VERSION ""

NS_ :

BS_:

BU_: VMCU VGGSECUSystem TECU OBDScanT2 HMIIOM EMS ECUspare2 ECUspare1 DACU CIOM BBM

BO_ 2495638185 VMCU_BB2_54P: 8 VMCU
 SG_ MaintOilQuality : 35|3@1+ (1,0) [0|0] ""  EMS
 SG_ FrontParkBrakeOverrideInd_ISig_4 : 53|2@1+ (1,0) [0|0] ""  HMIIOM
 SG_ ECSLimpHomeNotification_ISig_4 : 16|3@1+ (1,0) [0|0] ""  HMIIOM
 SG_ MirrorHeatUnavailable_Ind : 30|2@1+ (1,0) [0|0] ""  HMIIOM
 SG_ MaintenanceResetStatus : 19|3@1+ (1,0) [0|0] ""  HMIIOM
 SG_ ParkBrakeApplicationMode : 43|3@1+ (1,0) [0|0] ""  VGGSECUSystem,HMIIOM
 SG_ MaintOilReset : 38|2@1+ (1,0) [0|0] ""  EMS
 SG_ RssInhibStartEngine_rqst_ISig_4 : 6|2@1+ (1,0) [0|0] ""  HMIIOM
 SG_ PositionLightRequest_status : 2|2@1+ (1,0) [0|0] ""  BBM,HMIIOM
 SG_ ExtraBBTailLiftStatus_ISig_4 : 4|2@1+ (1,0) [0|0] ""  CIOM
 SG_ MaintenanceNotification_ISig_4 : 32|3@1+ (1,0) [0|0] ""  VGGSECUSystem,HMIIOM
 SG_ ExtraBBSlidable5thWheelStatus : 0|2@1+ (1,0) [0|0] ""  CIOM
 SG_ ParkBrakeReleasePossible_stat : 10|2@1+ (1,0) [0|0] ""  HMIIOM,VGGSECUSystem,TECU
 SG_ LoadDistributionALDChangeACK_ISi : 48|3@1+ (1,0) [0|0] ""  CIOM,HMIIOM
 SG_ PoorAirPressureInfo_UB_ISig_4 : 55|1@1+ (1,0) [0|0] ""  BBM,VGGSECUSystem,HMIIOM
 SG_ ParkBrakeReleaseMode_ISig_4 : 40|3@1+ (1,0) [0|0] ""  HMIIOM
 SG_ ParkBrakeWorkshopMode_ISig_4 : 14|2@1+ (1,0) [0|0] ""  HMIIOM
 SG_ ExtraBBContainerUnlockStatus : 46|2@1+ (1,0) [0|0] ""  CIOM
 SG_ MainBeamRequest_status_ISig_4 : 56|2@1+ (1,0) [0|0] ""  BBM,DACU
 SG_ ExtraBBCraneStatus_ISig_4 : 27|3@1+ (1,0) [0|0] ""  CIOM,BBM
 SG_ AirCompressorStatus : 58|2@1+ (1,0) [0|0] ""  EMS
 SG_ TrailerABSStatus_ISig_4 : 12|2@1+ (1,0) [0|0] ""  TECU,HMIIOM,EMS,DACU
 SG_ RegenInhibitVehicleHeight_ISig_4 : 22|2@1+ (1,0) [0|0] ""  EMS
 SG_ PoorAirPressureInfo_ISig_4 : 51|2@1+ (1,0) [0|0] ""  BBM,HMIIOM,VGGSECUSystem
 SG_ FogLightRearRequest_stat : 8|2@1+ (1,0) [0|0] ""  BBM
 SG_ MainBeam_cmd_ISig_4 : 60|3@1+ (1,0) [0|0] ""  BBM
 SG_ FirstAxleLowerPrioSelected_ISig_ : 24|3@1+ (1,0) [0|0] ""  HMIIOM

BO_ 2482995069 VMCU_BB2_53P: 8 VMCU
 SG_ AuxSwitchBbLoad4_cmd : 14|2@1+ (1,0) [0|0] ""  BBM
 SG_ AuxSwitchBbLoad1_Status_ISig_4 : 0|2@1+ (1,0) [0|0] ""  CIOM,BBM
 SG_ BrakeLightConvoy_rqst_UB_ISig_4 : 45|1@1+ (1,0) [0|0] ""  BBM
 SG_ AccPedalTestPresentationStatus : 51|3@1+ (1,0) [0|0] ""  HMIIOM,VGGSECUSystem
 SG_ AuxSwitchBbLoad3_cmd : 12|2@1+ (1,0) [0|0] ""  BBM
 SG_ BatterySOCTrustLevel_ISig_4 : 56|8@1+ (0.5,0) [0|127.5] "Percent"  HMIIOM
 SG_ AuxSwitchBbLoad4_Status_ISig_4 : 6|2@1+ (1,0) [0|0] ""  CIOM,BBM
 SG_ BrakeLightConvoy_rqst_ISig_4 : 30|2@1+ (1,0) [0|0] ""  BBM
 SG_ DoorWarningLight_cmd_ISig_4 : 38|2@1+ (1,0) [0|0] ""  CIOM
 SG_ BlackOutandConvoyMode_rqst_ISig_ : 35|3@1+ (1,0) [0|0] ""  HMIIOM,DACU,BBM
 SG_ DirIndicatorRqstLights_stat : 32|3@1+ (1,0) [0|0] ""  DACU,BBM
 SG_ DoubleFrontAxleSteeringWarning_I : 20|2@1+ (1,0) [0|0] ""  HMIIOM
 SG_ ASLActive : 22|2@1+ (1,0) [0|0] ""  HMIIOM
 SG_ DippedBeamRequest_status : 24|2@1+ (1,0) [0|0] ""  BBM
 SG_ AuxSwitchBbLoad3_Status_ISig_4 : 4|2@1+ (1,0) [0|0] ""  CIOM,BBM
 SG_ DoorInstepLight_cmd_ISig_4 : 43|2@1+ (1,0) [0|0] ""  CIOM
 SG_ DRLRequest_status : 26|2@1+ (1,0) [0|0] ""  BBM
 SG_ AuxSwitchBbLoad6_Status_ISig_4 : 10|2@1+ (1,0) [0|0] ""  BBM,CIOM
 SG_ AuxSwitchBbLoad2_Status_ISig_4 : 2|2@1+ (1,0) [0|0] ""  CIOM,BBM
 SG_ AuxSwitchBbLoad5_cmd : 16|2@1+ (1,0) [0|0] ""  BBM
 SG_ PBReleaseInhibit_EPBState_ISig_4 : 48|3@1+ (1,0) [0|0] ""  BBM
 SG_ ExtStaticTrailerBrake_Stat_ISig_ : 46|2@1+ (1,0) [0|0] ""  HMIIOM,BBM
 SG_ AuxSwitchBbLoad5_Status_ISig_4 : 8|2@1+ (1,0) [0|0] ""  CIOM,BBM
 SG_ AuxSwitchBbLoad6_cmd : 18|2@1+ (1,0) [0|0] ""  BBM

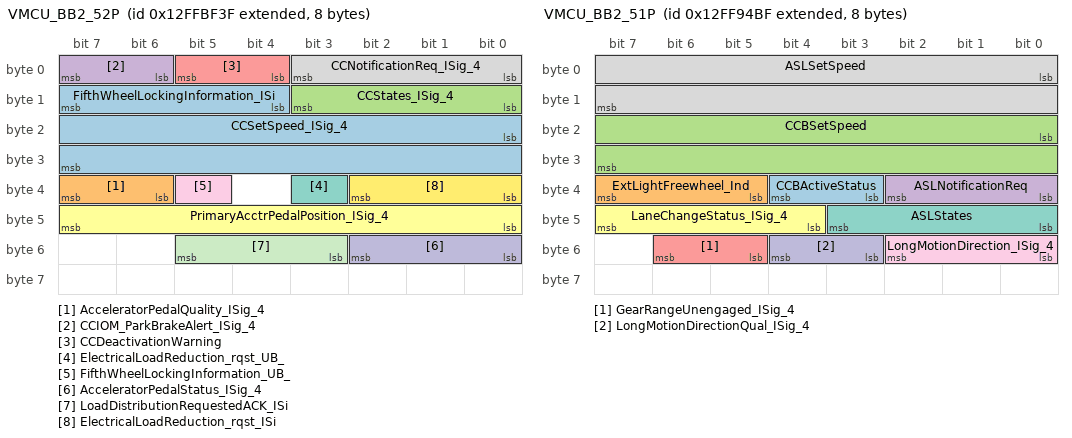
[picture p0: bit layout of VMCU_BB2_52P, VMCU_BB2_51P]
BO_ 2466234175 VMCU_BB2_52P: 8 VMCU
 SG_ CCSetSpeed_ISig_4 : 16|16@1+ (0.00390625,0) [0|255.99609375] "Km_per_h"  TECU,BBM,DACU,HMIIOM
 SG_ AcceleratorPedalQuality_ISig_4 : 38|2@1+ (1,0) [0|0] ""  BBM
 SG_ CCStates_ISig_4 : 8|4@1+ (1,0) [0|0] ""  CIOM,DACU,HMIIOM,BBM
 SG_ CCIOM_ParkBrakeAlert_ISig_4 : 6|2@1+ (1,0) [0|0] ""  HMIIOM
 SG_ CCDeactivationWarning : 4|2@1+ (1,0) [0|0] ""  DACU
 SG_ PrimaryAcctrPedalPosition_ISig_4 : 40|8@1+ (0.4,0) [0|102] "Percent"  BBM
 SG_ ElectricalLoadReduction_rqst_UB_ : 35|1@1+ (1,0) [0|0] ""  CIOM
 SG_ CCNotificationReq_ISig_4 : 0|4@1+ (1,0) [0|0] ""  HMIIOM
 SG_ FifthWheelLockingInformation_UB_ : 37|1@1+ (1,0) [0|0] ""  BBM,HMIIOM
 SG_ AcceleratorPedalStatus_ISig_4 : 48|3@1+ (1,0) [0|0] ""  CIOM,BBM
 SG_ LoadDistributionRequestedACK_ISi : 51|3@1+ (1,0) [0|0] ""  CIOM
 SG_ ElectricalLoadReduction_rqst_ISi : 32|3@1+ (1,0) [0|0] ""  CIOM
 SG_ FifthWheelLockingInformation_ISi : 12|4@1+ (1,0) [0|0] ""  HMIIOM

BO_ 2466223295 VMCU_BB2_51P: 8 VMCU
 SG_ CCBActiveStatus : 35|2@1+ (1,0) [0|0] ""  HMIIOM
 SG_ ExtLightFreewheel_Ind : 37|3@1+ (1,0) [0|0] ""  HMIIOM
 SG_ CCBSetSpeed : 16|16@1+ (0.00390625,0) [0|255.99609375] "Km_per_h"  DACU,TECU,HMIIOM
 SG_ ASLNotificationReq : 32|3@1+ (1,0) [0|0] ""  HMIIOM
 SG_ GearRangeUnengaged_ISig_4 : 53|2@1+ (1,0) [0|0] ""  HMIIOM
 SG_ LaneChangeStatus_ISig_4 : 44|4@1+ (1,0) [0|0] ""  DACU
 SG_ ASLStates : 40|4@1+ (1,0) [0|0] ""  CIOM,HMIIOM
 SG_ ASLSetSpeed : 0|16@1+ (0.00390625,0) [0|255.99609375] "Km_per_h"  HMIIOM
 SG_ LongMotionDirection_ISig_4 : 48|3@1+ (1,0) [0|0] ""  BBM,CIOM
 SG_ LongMotionDirectionQual_ISig_4 : 51|2@1+ (1,0) [0|0] ""  CIOM

BO_ 2499796773 VMCU_BB2_34S_FCM: 8 CIOM
 SG_ VMCU_BB2_34S_FCS : 0|64@1+ (1,0) [0|0] ""  VMCU

BO_ 2499796772 VMCU_BB2_34S: 16 VMCU
 SG_ KeyID_KeyAuthEncrypted : 0|128@1+ (1,0) [0|0] ""  CIOM

BO_ 2566560037 VMCU_BB2_33S_FCM: 8 HMIIOM
 SG_ VMCU_BB2_33S_FCS : 0|64@1+ (1,0) [0|0] ""  VMCU

CM_ SG_ 2466234175 CCSetSpeed_ISig_4 "65024 - 65279 Error ; 65280 - 65535 Not available";
CM_ SG_ 2466223295 CCBSetSpeed "65024 - 65279 Error ; 65280 - 65535 Not available";
CM_ SG_ 2466223295 ASLSetSpeed "65024 - 65279 Error ; 65280 - 65535 Not available";
BA_DEF_ BO_  "GenMsgStartDelayTime" INT 0 0;
BA_DEF_ BO_  "GenMsgDelayTime" INT 0 0;
BA_DEF_ BO_  "GenMsgCycleTime" INT 0 0;
BA_DEF_ BO_  "GenMsgSendType" ENUM  "Cyclic","NotUsed","NotUsed","NotUsed","NotUsed","NotUsed","NotUsed","IfActive","NoMsgSendType","NotUsed";
BA_DEF_ SG_  "GenSigStartValue" INT 0 0;
BA_DEF_ SG_  "GenSigCycleTimeActive" INT 0 0;
BA_DEF_ SG_  "GenSigCycleTime" INT 0 0;
BA_DEF_ SG_  "GenSigSendType" ENUM  "Cyclic","OnWrite","OnWriteWithRepetition","OnChange","OnChangeWithRepetition","IfActive","IfActiveWithRepetition","NoSigSendType","NotUsed","NotUsed","NotUsed","NotUsed","NotUsed";
BA_DEF_ BO_  "VFrameFormat" ENUM  "StandardCAN","ExtendedCAN","reserved","J1939PG";
BA_DEF_ SG_  "SigType" ENUM  "Default","Range","RangeSigned","ASCII","Discrete","Control","ReferencePGN","DTC","StringDelimiter","StringLength","StringLengthControl";
BA_DEF_ SG_  "SeToolVersion_SIGNAL" STRING ;
BA_DEF_ SG_  "SeToolUniqueID_SIGNAL" STRING ;
BA_DEF_ SG_  "SeToolOwnerSigGroup_SIGNAL" STRING ;
BA_DEF_ SG_  "SeToolOwnerSigGroupID_SIGNAL" STRING ;
BA_DEF_ SG_  "SeToolName_SIGNAL" STRING ;
BA_DEF_ SG_  "SeToolItemID_SIGNAL" STRING ;
BA_DEF_ SG_  "SeToolAncestorID_SIGNAL" STRING ;
BA_DEF_ SG_  "Platform_VMCU1_Sig" ENUM  "No","Yes";
BA_DEF_ BO_  "NmAsrMessage" ENUM  "No","Yes";
BA_DEF_ SG_  "NeedsUpdateBit" ENUM  "No","Yes";
BA_DEF_ SG_  "MmAnSignal" ENUM  "No","Yes";
BA_DEF_ SG_  "GenSigMaxLatency" INT 0 65535;
BA_DEF_ SG_  "GenSigILSupport" ENUM  "Yes","No";
BA_DEF_ BO_  "GenMsgRequestable" INT 0 1;
BA_DEF_ BO_  "GenMsgILSupport" ENUM  "No","Yes";
BA_DEF_ BO_  "DiagUUDTResponse" ENUM  "No","Yes";
BA_DEF_ BO_  "DiagState" ENUM  "No","Yes";
BA_DEF_ BO_  "DiagResponse" ENUM  "No","Yes";
BA_DEF_ BO_  "DiagRequest" ENUM  "No","Yes";
BA_DEF_ BO_  "DiagConnection" HEX 0 65535;
BA_DEF_ BO_  "CanTpSTmin" INT 0 255;
BA_DEF_ BO_  "CanTpFcFrameId" HEX 0 2147483647;
BA_DEF_ BO_  "CanTpBs" INT 0 255;
BA_DEF_ SG_  "SystemSignalLongSymbol" STRING ;
BA_DEF_REL_ BU_SG_REL_  "GenSigTimeoutTime" INT 0 65535;
BA_DEF_REL_ BU_SG_REL_  "GenSigFirstTimeoutTime" INT 0 65535;
BA_DEF_DEF_  "GenMsgStartDelayTime" 0;
BA_DEF_DEF_  "GenMsgDelayTime" 0;
BA_DEF_DEF_  "GenMsgCycleTime" 0;
BA_DEF_DEF_  "GenMsgSendType" "Cyclic";
BA_DEF_DEF_  "GenSigStartValue" 0;
BA_DEF_DEF_  "GenSigCycleTimeActive" 0;
BA_DEF_DEF_  "GenSigCycleTime" 0;
BA_DEF_DEF_  "GenSigSendType" "Cyclic";
BA_DEF_DEF_  "VFrameFormat" "ExtendedCAN";
BA_DEF_DEF_  "SigType" "Default";
BA_DEF_DEF_  "SeToolVersion_SIGNAL" "";
BA_DEF_DEF_  "SeToolUniqueID_SIGNAL" "";
BA_DEF_DEF_  "SeToolOwnerSigGroup_SIGNAL" "";
BA_DEF_DEF_  "SeToolOwnerSigGroupID_SIGNAL" "";
BA_DEF_DEF_  "SeToolName_SIGNAL" "";
BA_DEF_DEF_  "SeToolItemID_SIGNAL" "";
BA_DEF_DEF_  "SeToolAncestorID_SIGNAL" "";
BA_DEF_DEF_  "Platform_VMCU1_Sig" "No";
BA_DEF_DEF_  "NmAsrMessage" "No";
BA_DEF_DEF_  "NeedsUpdateBit" "No";
BA_DEF_DEF_  "MmAnSignal" "No";
BA_DEF_DEF_  "GenSigMaxLatency" 0;
BA_DEF_DEF_  "GenSigILSupport" "Yes";
BA_DEF_DEF_  "GenMsgRequestable" 1;
BA_DEF_DEF_  "GenMsgILSupport" "Yes";
BA_DEF_DEF_  "DiagUUDTResponse" "No";
BA_DEF_DEF_  "DiagState" "No";
BA_DEF_DEF_  "DiagResponse" "No";
BA_DEF_DEF_  "DiagRequest" "No";
BA_DEF_DEF_  "DiagConnection" 0;
BA_DEF_DEF_  "CanTpSTmin" 0;
BA_DEF_DEF_  "CanTpFcFrameId" 2147483647;
BA_DEF_DEF_  "CanTpBs" 255;
BA_DEF_DEF_REL_ "GenSigTimeoutTime" 0;
BA_DEF_DEF_REL_ "GenSigFirstTimeoutTime" 0;
BA_DEF_DEF_  "SystemSignalLongSymbol" "";
BA_ "GenMsgCycleTime" BO_ 2495638185 75;
BA_ "GenMsgStartDelayTime" BO_ 2495638185 10;
BA_ "GenMsgCycleTime" BO_ 2482995069 50;
BA_ "GenMsgStartDelayTime" BO_ 2482995069 15;
BA_ "GenMsgCycleTime" BO_ 2466234175 35;
BA_ "GenMsgCycleTime" BO_ 2466223295 30;
BA_ "GenMsgStartDelayTime" BO_ 2466223295 15;
BA_ "GenMsgILSupport" BO_ 2499796773 0;
BA_ "GenMsgSendType" BO_ 2499796773 8;
BA_ "CanTpFcFrameId" BO_ 2499796772 352313125;
BA_ "GenMsgSendType" BO_ 2499796772 8;
BA_ "GenMsgDelayTime" BO_ 2499796772 80;
BA_ "GenMsgILSupport" BO_ 2566560037 0;
BA_ "GenMsgSendType" BO_ 2566560037 8;
BA_ "GenSigCycleTime" SG_ 2495638185 MaintOilQuality 100;
BA_ "GenSigCycleTimeActive" SG_ 2495638185 MaintOilQuality 100;
BA_ "GenSigStartValue" SG_ 2495638185 MaintOilQuality 7;
BA_ "GenSigMaxLatency" SG_ 2495638185 MaintOilQuality 112;
BA_ "Platform_VMCU1_Sig" SG_ 2495638185 MaintOilQuality 1;
BA_ "GenSigCycleTime" SG_ 2495638185 FrontParkBrakeOverrideInd_ISig_4 100;
BA_ "GenSigCycleTimeActive" SG_ 2495638185 FrontParkBrakeOverrideInd_ISig_4 100;
BA_ "GenSigStartValue" SG_ 2495638185 FrontParkBrakeOverrideInd_ISig_4 3;
BA_ "Platform_VMCU1_Sig" SG_ 2495638185 FrontParkBrakeOverrideInd_ISig_4 1;
BA_ "GenSigCycleTime" SG_ 2495638185 ECSLimpHomeNotification_ISig_4 100;
BA_ "GenSigCycleTimeActive" SG_ 2495638185 ECSLimpHomeNotification_ISig_4 100;
BA_ "GenSigStartValue" SG_ 2495638185 ECSLimpHomeNotification_ISig_4 7;
BA_ "GenSigMaxLatency" SG_ 2495638185 ECSLimpHomeNotification_ISig_4 63;
BA_ "Platform_VMCU1_Sig" SG_ 2495638185 ECSLimpHomeNotification_ISig_4 1;
BA_ "GenSigCycleTime" SG_ 2495638185 MirrorHeatUnavailable_Ind 100;
BA_ "GenSigCycleTimeActive" SG_ 2495638185 MirrorHeatUnavailable_Ind 100;
BA_ "GenSigStartValue" SG_ 2495638185 MirrorHeatUnavailable_Ind 3;
BA_ "Platform_VMCU1_Sig" SG_ 2495638185 MirrorHeatUnavailable_Ind 1;
BA_ "GenSigCycleTime" SG_ 2495638185 MaintenanceResetStatus 100;
BA_ "GenSigCycleTimeActive" SG_ 2495638185 MaintenanceResetStatus 100;
BA_ "GenSigStartValue" SG_ 2495638185 MaintenanceResetStatus 7;
BA_ "Platform_VMCU1_Sig" SG_ 2495638185 MaintenanceResetStatus 1;
BA_ "GenSigCycleTime" SG_ 2495638185 ParkBrakeApplicationMode 100;
BA_ "GenSigCycleTimeActive" SG_ 2495638185 ParkBrakeApplicationMode 100;
BA_ "GenSigStartValue" SG_ 2495638185 ParkBrakeApplicationMode 7;
BA_ "GenSigMaxLatency" SG_ 2495638185 ParkBrakeApplicationMode 112;
BA_ "Platform_VMCU1_Sig" SG_ 2495638185 ParkBrakeApplicationMode 1;
BA_ "GenSigCycleTime" SG_ 2495638185 MaintOilReset 100;
BA_ "GenSigCycleTimeActive" SG_ 2495638185 MaintOilReset 100;
BA_ "GenSigStartValue" SG_ 2495638185 MaintOilReset 3;
BA_ "GenSigMaxLatency" SG_ 2495638185 MaintOilReset 112;
BA_ "Platform_VMCU1_Sig" SG_ 2495638185 MaintOilReset 1;
BA_ "GenSigCycleTime" SG_ 2495638185 RssInhibStartEngine_rqst_ISig_4 100;
BA_ "GenSigCycleTimeActive" SG_ 2495638185 RssInhibStartEngine_rqst_ISig_4 100;
BA_ "GenSigStartValue" SG_ 2495638185 RssInhibStartEngine_rqst_ISig_4 3;
BA_ "GenSigMaxLatency" SG_ 2495638185 RssInhibStartEngine_rqst_ISig_4 112;
BA_ "Platform_VMCU1_Sig" SG_ 2495638185 RssInhibStartEngine_rqst_ISig_4 1;
BA_ "GenSigCycleTime" SG_ 2495638185 PositionLightRequest_status 100;
BA_ "GenSigCycleTimeActive" SG_ 2495638185 PositionLightRequest_status 100;
BA_ "GenSigStartValue" SG_ 2495638185 PositionLightRequest_status 3;
BA_ "GenSigMaxLatency" SG_ 2495638185 PositionLightRequest_status 112;
BA_ "Platform_VMCU1_Sig" SG_ 2495638185 PositionLightRequest_status 1;
BA_ "GenSigCycleTime" SG_ 2495638185 ExtraBBTailLiftStatus_ISig_4 100;
BA_ "GenSigCycleTimeActive" SG_ 2495638185 ExtraBBTailLiftStatus_ISig_4 100;
BA_ "GenSigStartValue" SG_ 2495638185 ExtraBBTailLiftStatus_ISig_4 3;
BA_ "GenSigMaxLatency" SG_ 2495638185 ExtraBBTailLiftStatus_ISig_4 112;
BA_ "Platform_VMCU1_Sig" SG_ 2495638185 ExtraBBTailLiftStatus_ISig_4 1;
BA_ "GenSigCycleTime" SG_ 2495638185 MaintenanceNotification_ISig_4 100;
BA_ "GenSigCycleTimeActive" SG_ 2495638185 MaintenanceNotification_ISig_4 100;
BA_ "GenSigStartValue" SG_ 2495638185 MaintenanceNotification_ISig_4 7;
BA_ "GenSigMaxLatency" SG_ 2495638185 MaintenanceNotification_ISig_4 112;
BA_ "Platform_VMCU1_Sig" SG_ 2495638185 MaintenanceNotification_ISig_4 1;
BA_ "GenSigCycleTime" SG_ 2495638185 ExtraBBSlidable5thWheelStatus 100;
BA_ "GenSigCycleTimeActive" SG_ 2495638185 ExtraBBSlidable5thWheelStatus 100;
BA_ "GenSigStartValue" SG_ 2495638185 ExtraBBSlidable5thWheelStatus 3;
BA_ "GenSigMaxLatency" SG_ 2495638185 ExtraBBSlidable5thWheelStatus 112;
BA_ "Platform_VMCU1_Sig" SG_ 2495638185 ExtraBBSlidable5thWheelStatus 1;
BA_ "GenSigCycleTime" SG_ 2495638185 ParkBrakeReleasePossible_stat 100;
BA_ "GenSigCycleTimeActive" SG_ 2495638185 ParkBrakeReleasePossible_stat 100;
BA_ "GenSigStartValue" SG_ 2495638185 ParkBrakeReleasePossible_stat 3;
BA_ "GenSigMaxLatency" SG_ 2495638185 ParkBrakeReleasePossible_stat 112;
BA_ "Platform_VMCU1_Sig" SG_ 2495638185 ParkBrakeReleasePossible_stat 1;
BA_ "GenSigCycleTime" SG_ 2495638185 LoadDistributionALDChangeACK_ISi 100;
BA_ "GenSigCycleTimeActive" SG_ 2495638185 LoadDistributionALDChangeACK_ISi 100;
BA_ "GenSigStartValue" SG_ 2495638185 LoadDistributionALDChangeACK_ISi 7;
BA_ "GenSigMaxLatency" SG_ 2495638185 LoadDistributionALDChangeACK_ISi 112;
BA_ "Platform_VMCU1_Sig" SG_ 2495638185 LoadDistributionALDChangeACK_ISi 1;
BA_ "SystemSignalLongSymbol" SG_ 2495638185 LoadDistributionALDChangeACK_ISi "LoadDistributionALDChangeACK_ISig_4";
BA_ "GenSigSendType" SG_ 2495638185 PoorAirPressureInfo_UB_ISig_4 7;
BA_ "Platform_VMCU1_Sig" SG_ 2495638185 PoorAirPressureInfo_UB_ISig_4 1;
BA_ "GenSigCycleTime" SG_ 2495638185 ParkBrakeReleaseMode_ISig_4 100;
BA_ "GenSigCycleTimeActive" SG_ 2495638185 ParkBrakeReleaseMode_ISig_4 100;
BA_ "GenSigStartValue" SG_ 2495638185 ParkBrakeReleaseMode_ISig_4 7;
BA_ "GenSigMaxLatency" SG_ 2495638185 ParkBrakeReleaseMode_ISig_4 112;
BA_ "Platform_VMCU1_Sig" SG_ 2495638185 ParkBrakeReleaseMode_ISig_4 1;
BA_ "GenSigCycleTime" SG_ 2495638185 ParkBrakeWorkshopMode_ISig_4 100;
BA_ "GenSigCycleTimeActive" SG_ 2495638185 ParkBrakeWorkshopMode_ISig_4 100;
BA_ "GenSigStartValue" SG_ 2495638185 ParkBrakeWorkshopMode_ISig_4 3;
BA_ "GenSigMaxLatency" SG_ 2495638185 ParkBrakeWorkshopMode_ISig_4 112;
BA_ "Platform_VMCU1_Sig" SG_ 2495638185 ParkBrakeWorkshopMode_ISig_4 1;
BA_ "GenSigCycleTime" SG_ 2495638185 ExtraBBContainerUnlockStatus 100;
BA_ "GenSigCycleTimeActive" SG_ 2495638185 ExtraBBContainerUnlockStatus 100;
BA_ "GenSigStartValue" SG_ 2495638185 ExtraBBContainerUnlockStatus 3;
BA_ "GenSigMaxLatency" SG_ 2495638185 ExtraBBContainerUnlockStatus 112;
BA_ "Platform_VMCU1_Sig" SG_ 2495638185 ExtraBBContainerUnlockStatus 1;
BA_ "GenSigCycleTime" SG_ 2495638185 MainBeamRequest_status_ISig_4 100;
BA_ "GenSigCycleTimeActive" SG_ 2495638185 MainBeamRequest_status_ISig_4 100;
BA_ "GenSigStartValue" SG_ 2495638185 MainBeamRequest_status_ISig_4 3;
BA_ "GenSigMaxLatency" SG_ 2495638185 MainBeamRequest_status_ISig_4 112;
BA_ "Platform_VMCU1_Sig" SG_ 2495638185 MainBeamRequest_status_ISig_4 1;
BA_ "GenSigCycleTime" SG_ 2495638185 ExtraBBCraneStatus_ISig_4 100;
BA_ "GenSigCycleTimeActive" SG_ 2495638185 ExtraBBCraneStatus_ISig_4 100;
BA_ "GenSigStartValue" SG_ 2495638185 ExtraBBCraneStatus_ISig_4 7;
BA_ "GenSigMaxLatency" SG_ 2495638185 ExtraBBCraneStatus_ISig_4 112;
BA_ "Platform_VMCU1_Sig" SG_ 2495638185 ExtraBBCraneStatus_ISig_4 1;
BA_ "GenSigCycleTime" SG_ 2495638185 AirCompressorStatus 100;
BA_ "GenSigCycleTimeActive" SG_ 2495638185 AirCompressorStatus 100;
BA_ "GenSigStartValue" SG_ 2495638185 AirCompressorStatus 3;
BA_ "Platform_VMCU1_Sig" SG_ 2495638185 AirCompressorStatus 1;
BA_ "GenSigCycleTime" SG_ 2495638185 TrailerABSStatus_ISig_4 100;
BA_ "GenSigCycleTimeActive" SG_ 2495638185 TrailerABSStatus_ISig_4 100;
BA_ "GenSigStartValue" SG_ 2495638185 TrailerABSStatus_ISig_4 3;
BA_ "GenSigMaxLatency" SG_ 2495638185 TrailerABSStatus_ISig_4 112;
BA_ "Platform_VMCU1_Sig" SG_ 2495638185 TrailerABSStatus_ISig_4 1;
BA_ "GenSigCycleTime" SG_ 2495638185 RegenInhibitVehicleHeight_ISig_4 100;
BA_ "GenSigCycleTimeActive" SG_ 2495638185 RegenInhibitVehicleHeight_ISig_4 100;
BA_ "GenSigStartValue" SG_ 2495638185 RegenInhibitVehicleHeight_ISig_4 3;
BA_ "Platform_VMCU1_Sig" SG_ 2495638185 RegenInhibitVehicleHeight_ISig_4 1;
BA_ "GenSigCycleTime" SG_ 2495638185 PoorAirPressureInfo_ISig_4 100;
BA_ "GenSigCycleTimeActive" SG_ 2495638185 PoorAirPressureInfo_ISig_4 100;
BA_ "GenSigStartValue" SG_ 2495638185 PoorAirPressureInfo_ISig_4 3;
BA_ "GenSigMaxLatency" SG_ 2495638185 PoorAirPressureInfo_ISig_4 112;
BA_ "NeedsUpdateBit" SG_ 2495638185 PoorAirPressureInfo_ISig_4 1;
BA_ "Platform_VMCU1_Sig" SG_ 2495638185 PoorAirPressureInfo_ISig_4 1;
BA_ "GenSigCycleTime" SG_ 2495638185 FogLightRearRequest_stat 100;
BA_ "GenSigCycleTimeActive" SG_ 2495638185 FogLightRearRequest_stat 100;
BA_ "GenSigStartValue" SG_ 2495638185 FogLightRearRequest_stat 3;
BA_ "GenSigMaxLatency" SG_ 2495638185 FogLightRearRequest_stat 112;
BA_ "Platform_VMCU1_Sig" SG_ 2495638185 FogLightRearRequest_stat 1;
BA_ "GenSigCycleTime" SG_ 2495638185 MainBeam_cmd_ISig_4 100;
BA_ "GenSigCycleTimeActive" SG_ 2495638185 MainBeam_cmd_ISig_4 100;
BA_ "GenSigStartValue" SG_ 2495638185 MainBeam_cmd_ISig_4 7;
BA_ "Platform_VMCU1_Sig" SG_ 2495638185 MainBeam_cmd_ISig_4 1;
BA_ "SeToolAncestorID_SIGNAL" SG_ 2495638185 MainBeam_cmd_ISig_4 "x0000001D04134EB4";
BA_ "SeToolItemID_SIGNAL" SG_ 2495638185 MainBeam_cmd_ISig_4 "x0000001D04383E5C";
BA_ "SeToolName_SIGNAL" SG_ 2495638185 MainBeam_cmd_ISig_4 "MainBeam_cmd";
BA_ "SeToolVersion_SIGNAL" SG_ 2495638185 MainBeam_cmd_ISig_4 "4";
BA_ "GenSigCycleTime" SG_ 2495638185 FirstAxleLowerPrioSelected_ISig_ 100;
BA_ "GenSigCycleTimeActive" SG_ 2495638185 FirstAxleLowerPrioSelected_ISig_ 100;
BA_ "GenSigStartValue" SG_ 2495638185 FirstAxleLowerPrioSelected_ISig_ 7;
BA_ "GenSigMaxLatency" SG_ 2495638185 FirstAxleLowerPrioSelected_ISig_ 112;
BA_ "Platform_VMCU1_Sig" SG_ 2495638185 FirstAxleLowerPrioSelected_ISig_ 1;
BA_ "SystemSignalLongSymbol" SG_ 2495638185 FirstAxleLowerPrioSelected_ISig_ "FirstAxleLowerPrioSelected_ISig_4";
BA_ "GenSigCycleTime" SG_ 2482995069 AuxSwitchBbLoad4_cmd 100;
BA_ "GenSigCycleTimeActive" SG_ 2482995069 AuxSwitchBbLoad4_cmd 100;
BA_ "GenSigStartValue" SG_ 2482995069 AuxSwitchBbLoad4_cmd 3;
BA_ "GenSigMaxLatency" SG_ 2482995069 AuxSwitchBbLoad4_cmd 63;
BA_ "Platform_VMCU1_Sig" SG_ 2482995069 AuxSwitchBbLoad4_cmd 1;
BA_ "GenSigCycleTime" SG_ 2482995069 AuxSwitchBbLoad1_Status_ISig_4 100;
BA_ "GenSigCycleTimeActive" SG_ 2482995069 AuxSwitchBbLoad1_Status_ISig_4 100;
BA_ "GenSigStartValue" SG_ 2482995069 AuxSwitchBbLoad1_Status_ISig_4 3;
BA_ "GenSigMaxLatency" SG_ 2482995069 AuxSwitchBbLoad1_Status_ISig_4 63;
BA_ "Platform_VMCU1_Sig" SG_ 2482995069 AuxSwitchBbLoad1_Status_ISig_4 1;
BA_ "GenSigSendType" SG_ 2482995069 BrakeLightConvoy_rqst_UB_ISig_4 7;
BA_ "Platform_VMCU1_Sig" SG_ 2482995069 BrakeLightConvoy_rqst_UB_ISig_4 1;
BA_ "GenSigCycleTime" SG_ 2482995069 AccPedalTestPresentationStatus 100;
BA_ "GenSigCycleTimeActive" SG_ 2482995069 AccPedalTestPresentationStatus 100;
BA_ "GenSigStartValue" SG_ 2482995069 AccPedalTestPresentationStatus 7;
BA_ "Platform_VMCU1_Sig" SG_ 2482995069 AccPedalTestPresentationStatus 1;
BA_ "GenSigCycleTime" SG_ 2482995069 AuxSwitchBbLoad3_cmd 100;
BA_ "GenSigCycleTimeActive" SG_ 2482995069 AuxSwitchBbLoad3_cmd 100;
BA_ "GenSigStartValue" SG_ 2482995069 AuxSwitchBbLoad3_cmd 3;
BA_ "GenSigMaxLatency" SG_ 2482995069 AuxSwitchBbLoad3_cmd 63;
BA_ "Platform_VMCU1_Sig" SG_ 2482995069 AuxSwitchBbLoad3_cmd 1;
BA_ "GenSigCycleTime" SG_ 2482995069 BatterySOCTrustLevel_ISig_4 100;
BA_ "GenSigCycleTimeActive" SG_ 2482995069 BatterySOCTrustLevel_ISig_4 100;
BA_ "GenSigStartValue" SG_ 2482995069 BatterySOCTrustLevel_ISig_4 255;
BA_ "Platform_VMCU1_Sig" SG_ 2482995069 BatterySOCTrustLevel_ISig_4 1;
BA_ "GenSigCycleTime" SG_ 2482995069 AuxSwitchBbLoad4_Status_ISig_4 100;
BA_ "GenSigCycleTimeActive" SG_ 2482995069 AuxSwitchBbLoad4_Status_ISig_4 100;
BA_ "GenSigStartValue" SG_ 2482995069 AuxSwitchBbLoad4_Status_ISig_4 3;
BA_ "GenSigMaxLatency" SG_ 2482995069 AuxSwitchBbLoad4_Status_ISig_4 63;
BA_ "Platform_VMCU1_Sig" SG_ 2482995069 AuxSwitchBbLoad4_Status_ISig_4 1;
BA_ "GenSigCycleTime" SG_ 2482995069 BrakeLightConvoy_rqst_ISig_4 100;
BA_ "GenSigCycleTimeActive" SG_ 2482995069 BrakeLightConvoy_rqst_ISig_4 100;
BA_ "GenSigStartValue" SG_ 2482995069 BrakeLightConvoy_rqst_ISig_4 3;
BA_ "NeedsUpdateBit" SG_ 2482995069 BrakeLightConvoy_rqst_ISig_4 1;
BA_ "Platform_VMCU1_Sig" SG_ 2482995069 BrakeLightConvoy_rqst_ISig_4 1;
BA_ "GenSigCycleTime" SG_ 2482995069 DoorWarningLight_cmd_ISig_4 100;
BA_ "GenSigCycleTimeActive" SG_ 2482995069 DoorWarningLight_cmd_ISig_4 100;
BA_ "GenSigStartValue" SG_ 2482995069 DoorWarningLight_cmd_ISig_4 3;
BA_ "Platform_VMCU1_Sig" SG_ 2482995069 DoorWarningLight_cmd_ISig_4 1;
BA_ "GenSigCycleTime" SG_ 2482995069 BlackOutandConvoyMode_rqst_ISig_ 100;
BA_ "GenSigCycleTimeActive" SG_ 2482995069 BlackOutandConvoyMode_rqst_ISig_ 100;
BA_ "GenSigStartValue" SG_ 2482995069 BlackOutandConvoyMode_rqst_ISig_ 7;
BA_ "Platform_VMCU1_Sig" SG_ 2482995069 BlackOutandConvoyMode_rqst_ISig_ 1;
BA_ "SystemSignalLongSymbol" SG_ 2482995069 BlackOutandConvoyMode_rqst_ISig_ "BlackOutandConvoyMode_rqst_ISig_4";
BA_ "GenSigCycleTime" SG_ 2482995069 DirIndicatorRqstLights_stat 100;
BA_ "GenSigCycleTimeActive" SG_ 2482995069 DirIndicatorRqstLights_stat 100;
BA_ "GenSigStartValue" SG_ 2482995069 DirIndicatorRqstLights_stat 7;
BA_ "GenSigMaxLatency" SG_ 2482995069 DirIndicatorRqstLights_stat 63;
BA_ "Platform_VMCU1_Sig" SG_ 2482995069 DirIndicatorRqstLights_stat 1;
BA_ "GenSigCycleTime" SG_ 2482995069 DoubleFrontAxleSteeringWarning_I 100;
BA_ "GenSigCycleTimeActive" SG_ 2482995069 DoubleFrontAxleSteeringWarning_I 100;
BA_ "GenSigStartValue" SG_ 2482995069 DoubleFrontAxleSteeringWarning_I 3;
BA_ "GenSigMaxLatency" SG_ 2482995069 DoubleFrontAxleSteeringWarning_I 63;
BA_ "Platform_VMCU1_Sig" SG_ 2482995069 DoubleFrontAxleSteeringWarning_I 1;
BA_ "SystemSignalLongSymbol" SG_ 2482995069 DoubleFrontAxleSteeringWarning_I "DoubleFrontAxleSteeringWarning_ISig_4";
BA_ "GenSigCycleTime" SG_ 2482995069 ASLActive 100;
BA_ "GenSigCycleTimeActive" SG_ 2482995069 ASLActive 100;
BA_ "GenSigStartValue" SG_ 2482995069 ASLActive 3;
BA_ "GenSigMaxLatency" SG_ 2482995069 ASLActive 63;
BA_ "Platform_VMCU1_Sig" SG_ 2482995069 ASLActive 1;
BA_ "GenSigCycleTime" SG_ 2482995069 DippedBeamRequest_status 100;
BA_ "GenSigCycleTimeActive" SG_ 2482995069 DippedBeamRequest_status 100;
BA_ "GenSigStartValue" SG_ 2482995069 DippedBeamRequest_status 3;
BA_ "GenSigMaxLatency" SG_ 2482995069 DippedBeamRequest_status 63;
BA_ "Platform_VMCU1_Sig" SG_ 2482995069 DippedBeamRequest_status 1;
BA_ "GenSigCycleTime" SG_ 2482995069 AuxSwitchBbLoad3_Status_ISig_4 100;
BA_ "GenSigCycleTimeActive" SG_ 2482995069 AuxSwitchBbLoad3_Status_ISig_4 100;
BA_ "GenSigStartValue" SG_ 2482995069 AuxSwitchBbLoad3_Status_ISig_4 3;
BA_ "GenSigMaxLatency" SG_ 2482995069 AuxSwitchBbLoad3_Status_ISig_4 63;
BA_ "Platform_VMCU1_Sig" SG_ 2482995069 AuxSwitchBbLoad3_Status_ISig_4 1;
BA_ "GenSigCycleTime" SG_ 2482995069 DoorInstepLight_cmd_ISig_4 100;
BA_ "GenSigCycleTimeActive" SG_ 2482995069 DoorInstepLight_cmd_ISig_4 100;
BA_ "GenSigStartValue" SG_ 2482995069 DoorInstepLight_cmd_ISig_4 3;
BA_ "Platform_VMCU1_Sig" SG_ 2482995069 DoorInstepLight_cmd_ISig_4 1;
BA_ "GenSigCycleTime" SG_ 2482995069 DRLRequest_status 100;
BA_ "GenSigCycleTimeActive" SG_ 2482995069 DRLRequest_status 100;
BA_ "GenSigStartValue" SG_ 2482995069 DRLRequest_status 3;
BA_ "GenSigMaxLatency" SG_ 2482995069 DRLRequest_status 63;
BA_ "Platform_VMCU1_Sig" SG_ 2482995069 DRLRequest_status 1;
BA_ "GenSigCycleTime" SG_ 2482995069 AuxSwitchBbLoad6_Status_ISig_4 100;
BA_ "GenSigCycleTimeActive" SG_ 2482995069 AuxSwitchBbLoad6_Status_ISig_4 100;
BA_ "GenSigStartValue" SG_ 2482995069 AuxSwitchBbLoad6_Status_ISig_4 3;
BA_ "GenSigMaxLatency" SG_ 2482995069 AuxSwitchBbLoad6_Status_ISig_4 63;
BA_ "Platform_VMCU1_Sig" SG_ 2482995069 AuxSwitchBbLoad6_Status_ISig_4 1;
BA_ "GenSigCycleTime" SG_ 2482995069 AuxSwitchBbLoad2_Status_ISig_4 100;
BA_ "GenSigCycleTimeActive" SG_ 2482995069 AuxSwitchBbLoad2_Status_ISig_4 100;
BA_ "GenSigStartValue" SG_ 2482995069 AuxSwitchBbLoad2_Status_ISig_4 3;
BA_ "GenSigMaxLatency" SG_ 2482995069 AuxSwitchBbLoad2_Status_ISig_4 63;
BA_ "Platform_VMCU1_Sig" SG_ 2482995069 AuxSwitchBbLoad2_Status_ISig_4 1;
BA_ "GenSigCycleTime" SG_ 2482995069 AuxSwitchBbLoad5_cmd 100;
BA_ "GenSigCycleTimeActive" SG_ 2482995069 AuxSwitchBbLoad5_cmd 100;
BA_ "GenSigStartValue" SG_ 2482995069 AuxSwitchBbLoad5_cmd 3;
BA_ "GenSigMaxLatency" SG_ 2482995069 AuxSwitchBbLoad5_cmd 63;
BA_ "Platform_VMCU1_Sig" SG_ 2482995069 AuxSwitchBbLoad5_cmd 1;
BA_ "GenSigCycleTime" SG_ 2482995069 PBReleaseInhibit_EPBState_ISig_4 100;
BA_ "GenSigCycleTimeActive" SG_ 2482995069 PBReleaseInhibit_EPBState_ISig_4 100;
BA_ "GenSigStartValue" SG_ 2482995069 PBReleaseInhibit_EPBState_ISig_4 7;
BA_ "Platform_VMCU1_Sig" SG_ 2482995069 PBReleaseInhibit_EPBState_ISig_4 1;
BA_ "GenSigCycleTime" SG_ 2482995069 ExtStaticTrailerBrake_Stat_ISig_ 100;
BA_ "GenSigCycleTimeActive" SG_ 2482995069 ExtStaticTrailerBrake_Stat_ISig_ 100;
BA_ "GenSigStartValue" SG_ 2482995069 ExtStaticTrailerBrake_Stat_ISig_ 3;
BA_ "Platform_VMCU1_Sig" SG_ 2482995069 ExtStaticTrailerBrake_Stat_ISig_ 1;
BA_ "SystemSignalLongSymbol" SG_ 2482995069 ExtStaticTrailerBrake_Stat_ISig_ "ExtStaticTrailerBrake_Stat_ISig_4";
BA_ "GenSigCycleTime" SG_ 2482995069 AuxSwitchBbLoad5_Status_ISig_4 100;
BA_ "GenSigCycleTimeActive" SG_ 2482995069 AuxSwitchBbLoad5_Status_ISig_4 100;
BA_ "GenSigStartValue" SG_ 2482995069 AuxSwitchBbLoad5_Status_ISig_4 3;
BA_ "GenSigMaxLatency" SG_ 2482995069 AuxSwitchBbLoad5_Status_ISig_4 63;
BA_ "Platform_VMCU1_Sig" SG_ 2482995069 AuxSwitchBbLoad5_Status_ISig_4 1;
BA_ "GenSigCycleTime" SG_ 2482995069 AuxSwitchBbLoad6_cmd 100;
BA_ "GenSigCycleTimeActive" SG_ 2482995069 AuxSwitchBbLoad6_cmd 100;
BA_ "GenSigStartValue" SG_ 2482995069 AuxSwitchBbLoad6_cmd 3;
BA_ "GenSigMaxLatency" SG_ 2482995069 AuxSwitchBbLoad6_cmd 63;
BA_ "Platform_VMCU1_Sig" SG_ 2482995069 AuxSwitchBbLoad6_cmd 1;
BA_ "GenSigCycleTime" SG_ 2466234175 CCSetSpeed_ISig_4 100;
BA_ "GenSigCycleTimeActive" SG_ 2466234175 CCSetSpeed_ISig_4 100;
BA_ "GenSigStartValue" SG_ 2466234175 CCSetSpeed_ISig_4 65535;
BA_ "GenSigMaxLatency" SG_ 2466234175 CCSetSpeed_ISig_4 40;
BA_ "Platform_VMCU1_Sig" SG_ 2466234175 CCSetSpeed_ISig_4 1;
BA_ "GenSigCycleTime" SG_ 2466234175 AcceleratorPedalQuality_ISig_4 100;
BA_ "GenSigCycleTimeActive" SG_ 2466234175 AcceleratorPedalQuality_ISig_4 100;
BA_ "GenSigStartValue" SG_ 2466234175 AcceleratorPedalQuality_ISig_4 3;
BA_ "Platform_VMCU1_Sig" SG_ 2466234175 AcceleratorPedalQuality_ISig_4 1;
BA_ "GenSigCycleTime" SG_ 2466234175 CCStates_ISig_4 100;
BA_ "GenSigCycleTimeActive" SG_ 2466234175 CCStates_ISig_4 100;
BA_ "GenSigStartValue" SG_ 2466234175 CCStates_ISig_4 15;
BA_ "GenSigMaxLatency" SG_ 2466234175 CCStates_ISig_4 40;
BA_ "Platform_VMCU1_Sig" SG_ 2466234175 CCStates_ISig_4 1;
BA_ "GenSigCycleTime" SG_ 2466234175 CCIOM_ParkBrakeAlert_ISig_4 100;
BA_ "GenSigCycleTimeActive" SG_ 2466234175 CCIOM_ParkBrakeAlert_ISig_4 100;
BA_ "GenSigStartValue" SG_ 2466234175 CCIOM_ParkBrakeAlert_ISig_4 3;
BA_ "Platform_VMCU1_Sig" SG_ 2466234175 CCIOM_ParkBrakeAlert_ISig_4 1;
BA_ "GenSigCycleTime" SG_ 2466234175 CCDeactivationWarning 100;
BA_ "GenSigCycleTimeActive" SG_ 2466234175 CCDeactivationWarning 100;
BA_ "GenSigStartValue" SG_ 2466234175 CCDeactivationWarning 3;
BA_ "GenSigMaxLatency" SG_ 2466234175 CCDeactivationWarning 40;
BA_ "Platform_VMCU1_Sig" SG_ 2466234175 CCDeactivationWarning 1;
BA_ "SeToolAncestorID_SIGNAL" SG_ 2466234175 CCDeactivationWarning "x0000001D04184560";
BA_ "SeToolItemID_SIGNAL" SG_ 2466234175 CCDeactivationWarning "x0000001D043C571E";
BA_ "SeToolName_SIGNAL" SG_ 2466234175 CCDeactivationWarning "CCDeactivationWarning";
BA_ "SeToolVersion_SIGNAL" SG_ 2466234175 CCDeactivationWarning "2";
BA_ "GenSigCycleTime" SG_ 2466234175 PrimaryAcctrPedalPosition_ISig_4 100;
BA_ "GenSigCycleTimeActive" SG_ 2466234175 PrimaryAcctrPedalPosition_ISig_4 100;
BA_ "GenSigStartValue" SG_ 2466234175 PrimaryAcctrPedalPosition_ISig_4 255;
BA_ "Platform_VMCU1_Sig" SG_ 2466234175 PrimaryAcctrPedalPosition_ISig_4 1;
BA_ "GenSigSendType" SG_ 2466234175 ElectricalLoadReduction_rqst_UB_ 7;
BA_ "Platform_VMCU1_Sig" SG_ 2466234175 ElectricalLoadReduction_rqst_UB_ 1;
BA_ "SystemSignalLongSymbol" SG_ 2466234175 ElectricalLoadReduction_rqst_UB_ "ElectricalLoadReduction_rqst_UB_ISig_4";
BA_ "GenSigCycleTime" SG_ 2466234175 CCNotificationReq_ISig_4 100;
BA_ "GenSigCycleTimeActive" SG_ 2466234175 CCNotificationReq_ISig_4 100;
BA_ "GenSigStartValue" SG_ 2466234175 CCNotificationReq_ISig_4 15;
BA_ "GenSigMaxLatency" SG_ 2466234175 CCNotificationReq_ISig_4 40;
BA_ "Platform_VMCU1_Sig" SG_ 2466234175 CCNotificationReq_ISig_4 1;
BA_ "SeToolAncestorID_SIGNAL" SG_ 2466234175 CCNotificationReq_ISig_4 "x0000001D0418455E";
BA_ "SeToolItemID_SIGNAL" SG_ 2466234175 CCNotificationReq_ISig_4 "x0000001D043A835E";
BA_ "SeToolName_SIGNAL" SG_ 2466234175 CCNotificationReq_ISig_4 "CCInformationMessageRequest";
BA_ "SeToolVersion_SIGNAL" SG_ 2466234175 CCNotificationReq_ISig_4 "3";
BA_ "GenSigSendType" SG_ 2466234175 FifthWheelLockingInformation_UB_ 7;
BA_ "Platform_VMCU1_Sig" SG_ 2466234175 FifthWheelLockingInformation_UB_ 1;
BA_ "SystemSignalLongSymbol" SG_ 2466234175 FifthWheelLockingInformation_UB_ "FifthWheelLockingInformation_UB_ISig_4";
BA_ "GenSigCycleTime" SG_ 2466234175 AcceleratorPedalStatus_ISig_4 100;
BA_ "GenSigCycleTimeActive" SG_ 2466234175 AcceleratorPedalStatus_ISig_4 100;
BA_ "GenSigStartValue" SG_ 2466234175 AcceleratorPedalStatus_ISig_4 7;
BA_ "Platform_VMCU1_Sig" SG_ 2466234175 AcceleratorPedalStatus_ISig_4 1;
BA_ "GenSigCycleTime" SG_ 2466234175 LoadDistributionRequestedACK_ISi 100;
BA_ "GenSigCycleTimeActive" SG_ 2466234175 LoadDistributionRequestedACK_ISi 100;
BA_ "GenSigStartValue" SG_ 2466234175 LoadDistributionRequestedACK_ISi 7;
BA_ "Platform_VMCU1_Sig" SG_ 2466234175 LoadDistributionRequestedACK_ISi 1;
BA_ "SystemSignalLongSymbol" SG_ 2466234175 LoadDistributionRequestedACK_ISi "LoadDistributionRequestedACK_ISig_4";
BA_ "GenSigCycleTime" SG_ 2466234175 ElectricalLoadReduction_rqst_ISi 100;
BA_ "GenSigCycleTimeActive" SG_ 2466234175 ElectricalLoadReduction_rqst_ISi 100;
BA_ "GenSigStartValue" SG_ 2466234175 ElectricalLoadReduction_rqst_ISi 7;
BA_ "NeedsUpdateBit" SG_ 2466234175 ElectricalLoadReduction_rqst_ISi 1;
BA_ "Platform_VMCU1_Sig" SG_ 2466234175 ElectricalLoadReduction_rqst_ISi 1;
BA_ "SystemSignalLongSymbol" SG_ 2466234175 ElectricalLoadReduction_rqst_ISi "ElectricalLoadReduction_rqst_ISig_4";
BA_ "GenSigCycleTime" SG_ 2466234175 FifthWheelLockingInformation_ISi 100;
BA_ "GenSigCycleTimeActive" SG_ 2466234175 FifthWheelLockingInformation_ISi 100;
BA_ "GenSigStartValue" SG_ 2466234175 FifthWheelLockingInformation_ISi 15;
BA_ "GenSigMaxLatency" SG_ 2466234175 FifthWheelLockingInformation_ISi 112;
BA_ "NeedsUpdateBit" SG_ 2466234175 FifthWheelLockingInformation_ISi 1;
BA_ "Platform_VMCU1_Sig" SG_ 2466234175 FifthWheelLockingInformation_ISi 1;
BA_ "SystemSignalLongSymbol" SG_ 2466234175 FifthWheelLockingInformation_ISi "FifthWheelLockingInformation_ISig_4";
BA_ "GenSigCycleTime" SG_ 2466223295 CCBActiveStatus 100;
BA_ "GenSigCycleTimeActive" SG_ 2466223295 CCBActiveStatus 100;
BA_ "GenSigStartValue" SG_ 2466223295 CCBActiveStatus 3;
BA_ "GenSigMaxLatency" SG_ 2466223295 CCBActiveStatus 34;
BA_ "Platform_VMCU1_Sig" SG_ 2466223295 CCBActiveStatus 1;
BA_ "GenSigCycleTime" SG_ 2466223295 ExtLightFreewheel_Ind 100;
BA_ "GenSigCycleTimeActive" SG_ 2466223295 ExtLightFreewheel_Ind 100;
BA_ "GenSigStartValue" SG_ 2466223295 ExtLightFreewheel_Ind 7;
BA_ "Platform_VMCU1_Sig" SG_ 2466223295 ExtLightFreewheel_Ind 1;
BA_ "GenSigCycleTime" SG_ 2466223295 CCBSetSpeed 100;
BA_ "GenSigCycleTimeActive" SG_ 2466223295 CCBSetSpeed 100;
BA_ "GenSigStartValue" SG_ 2466223295 CCBSetSpeed 65535;
BA_ "GenSigMaxLatency" SG_ 2466223295 CCBSetSpeed 34;
BA_ "Platform_VMCU1_Sig" SG_ 2466223295 CCBSetSpeed 1;
BA_ "GenSigCycleTime" SG_ 2466223295 ASLNotificationReq 100;
BA_ "GenSigCycleTimeActive" SG_ 2466223295 ASLNotificationReq 100;
BA_ "GenSigStartValue" SG_ 2466223295 ASLNotificationReq 7;
BA_ "GenSigMaxLatency" SG_ 2466223295 ASLNotificationReq 34;
BA_ "Platform_VMCU1_Sig" SG_ 2466223295 ASLNotificationReq 1;
BA_ "GenSigCycleTime" SG_ 2466223295 GearRangeUnengaged_ISig_4 100;
BA_ "GenSigCycleTimeActive" SG_ 2466223295 GearRangeUnengaged_ISig_4 100;
BA_ "GenSigStartValue" SG_ 2466223295 GearRangeUnengaged_ISig_4 3;
BA_ "GenSigMaxLatency" SG_ 2466223295 GearRangeUnengaged_ISig_4 20;
BA_ "Platform_VMCU1_Sig" SG_ 2466223295 GearRangeUnengaged_ISig_4 1;
BA_ "GenSigCycleTime" SG_ 2466223295 LaneChangeStatus_ISig_4 100;
BA_ "GenSigCycleTimeActive" SG_ 2466223295 LaneChangeStatus_ISig_4 100;
BA_ "GenSigStartValue" SG_ 2466223295 LaneChangeStatus_ISig_4 15;
BA_ "Platform_VMCU1_Sig" SG_ 2466223295 LaneChangeStatus_ISig_4 1;
BA_ "GenSigCycleTime" SG_ 2466223295 ASLStates 100;
BA_ "GenSigCycleTimeActive" SG_ 2466223295 ASLStates 100;
BA_ "GenSigStartValue" SG_ 2466223295 ASLStates 15;
BA_ "GenSigMaxLatency" SG_ 2466223295 ASLStates 34;
BA_ "Platform_VMCU1_Sig" SG_ 2466223295 ASLStates 1;
BA_ "GenSigCycleTime" SG_ 2466223295 ASLSetSpeed 100;
BA_ "GenSigCycleTimeActive" SG_ 2466223295 ASLSetSpeed 100;
BA_ "GenSigStartValue" SG_ 2466223295 ASLSetSpeed 65535;
BA_ "GenSigMaxLatency" SG_ 2466223295 ASLSetSpeed 34;
BA_ "Platform_VMCU1_Sig" SG_ 2466223295 ASLSetSpeed 1;
BA_ "GenSigCycleTime" SG_ 2466223295 LongMotionDirection_ISig_4 20;
BA_ "GenSigCycleTimeActive" SG_ 2466223295 LongMotionDirection_ISig_4 100;
BA_ "GenSigStartValue" SG_ 2466223295 LongMotionDirection_ISig_4 7;
BA_ "GenSigMaxLatency" SG_ 2466223295 LongMotionDirection_ISig_4 20;
BA_ "Platform_VMCU1_Sig" SG_ 2466223295 LongMotionDirection_ISig_4 1;
BA_ "GenSigCycleTime" SG_ 2466223295 LongMotionDirectionQual_ISig_4 20;
BA_ "GenSigCycleTimeActive" SG_ 2466223295 LongMotionDirectionQual_ISig_4 100;
BA_ "GenSigStartValue" SG_ 2466223295 LongMotionDirectionQual_ISig_4 3;
BA_ "GenSigMaxLatency" SG_ 2466223295 LongMotionDirectionQual_ISig_4 20;
BA_ "Platform_VMCU1_Sig" SG_ 2466223295 LongMotionDirectionQual_ISig_4 1;
BA_ "GenSigSendType" SG_ 2499796773 VMCU_BB2_34S_FCS 7;
BA_ "Platform_VMCU1_Sig" SG_ 2499796773 VMCU_BB2_34S_FCS 1;
BA_ "GenSigSendType" SG_ 2499796772 KeyID_KeyAuthEncrypted 1;
BA_ "GenSigMaxLatency" SG_ 2499796772 KeyID_KeyAuthEncrypted 100;
BA_ "Platform_VMCU1_Sig" SG_ 2499796772 KeyID_KeyAuthEncrypted 1;
BA_ "GenSigSendType" SG_ 2566560037 VMCU_BB2_33S_FCS 7;
BA_ "Platform_VMCU1_Sig" SG_ 2566560037 VMCU_BB2_33S_FCS 1;
BA_REL_ "GenSigFirstTimeoutTime" BU_SG_REL_ EMS SG_ 2495638185 MaintOilQuality 3000;
BA_REL_ "GenSigTimeoutTime" BU_SG_REL_ EMS SG_ 2495638185 MaintOilQuality 450;
BA_REL_ "GenSigFirstTimeoutTime" BU_SG_REL_ HMIIOM SG_ 2495638185 FrontParkBrakeOverrideInd_ISig_4 3000;
BA_REL_ "GenSigTimeoutTime" BU_SG_REL_ HMIIOM SG_ 2495638185 FrontParkBrakeOverrideInd_ISig_4 450;
BA_REL_ "GenSigFirstTimeoutTime" BU_SG_REL_ HMIIOM SG_ 2495638185 ECSLimpHomeNotification_ISig_4 3000;
BA_REL_ "GenSigTimeoutTime" BU_SG_REL_ HMIIOM SG_ 2495638185 ECSLimpHomeNotification_ISig_4 450;
BA_REL_ "GenSigFirstTimeoutTime" BU_SG_REL_ HMIIOM SG_ 2495638185 MirrorHeatUnavailable_Ind 3000;
BA_REL_ "GenSigTimeoutTime" BU_SG_REL_ HMIIOM SG_ 2495638185 MirrorHeatUnavailable_Ind 450;
BA_REL_ "GenSigFirstTimeoutTime" BU_SG_REL_ HMIIOM SG_ 2495638185 MaintenanceResetStatus 3000;
BA_REL_ "GenSigTimeoutTime" BU_SG_REL_ HMIIOM SG_ 2495638185 MaintenanceResetStatus 450;
BA_REL_ "GenSigFirstTimeoutTime" BU_SG_REL_ VGGSECUSystem SG_ 2495638185 ParkBrakeApplicationMode 3000;
BA_REL_ "GenSigTimeoutTime" BU_SG_REL_ VGGSECUSystem SG_ 2495638185 ParkBrakeApplicationMode 450;
BA_REL_ "GenSigFirstTimeoutTime" BU_SG_REL_ HMIIOM SG_ 2495638185 ParkBrakeApplicationMode 3000;
BA_REL_ "GenSigTimeoutTime" BU_SG_REL_ HMIIOM SG_ 2495638185 ParkBrakeApplicationMode 450;
BA_REL_ "GenSigFirstTimeoutTime" BU_SG_REL_ EMS SG_ 2495638185 MaintOilReset 3000;
BA_REL_ "GenSigTimeoutTime" BU_SG_REL_ EMS SG_ 2495638185 MaintOilReset 450;
BA_REL_ "GenSigFirstTimeoutTime" BU_SG_REL_ HMIIOM SG_ 2495638185 RssInhibStartEngine_rqst_ISig_4 3000;
BA_REL_ "GenSigTimeoutTime" BU_SG_REL_ HMIIOM SG_ 2495638185 RssInhibStartEngine_rqst_ISig_4 450;
BA_REL_ "GenSigFirstTimeoutTime" BU_SG_REL_ BBM SG_ 2495638185 PositionLightRequest_status 3000;
BA_REL_ "GenSigTimeoutTime" BU_SG_REL_ BBM SG_ 2495638185 PositionLightRequest_status 450;
BA_REL_ "GenSigFirstTimeoutTime" BU_SG_REL_ HMIIOM SG_ 2495638185 PositionLightRequest_status 3000;
BA_REL_ "GenSigTimeoutTime" BU_SG_REL_ HMIIOM SG_ 2495638185 PositionLightRequest_status 450;
BA_REL_ "GenSigFirstTimeoutTime" BU_SG_REL_ CIOM SG_ 2495638185 ExtraBBTailLiftStatus_ISig_4 3000;
BA_REL_ "GenSigTimeoutTime" BU_SG_REL_ CIOM SG_ 2495638185 ExtraBBTailLiftStatus_ISig_4 450;
BA_REL_ "GenSigFirstTimeoutTime" BU_SG_REL_ VGGSECUSystem SG_ 2495638185 MaintenanceNotification_ISig_4 3000;
BA_REL_ "GenSigTimeoutTime" BU_SG_REL_ VGGSECUSystem SG_ 2495638185 MaintenanceNotification_ISig_4 450;
BA_REL_ "GenSigFirstTimeoutTime" BU_SG_REL_ HMIIOM SG_ 2495638185 MaintenanceNotification_ISig_4 3000;
BA_REL_ "GenSigTimeoutTime" BU_SG_REL_ HMIIOM SG_ 2495638185 MaintenanceNotification_ISig_4 450;
BA_REL_ "GenSigFirstTimeoutTime" BU_SG_REL_ CIOM SG_ 2495638185 ExtraBBSlidable5thWheelStatus 3000;
BA_REL_ "GenSigTimeoutTime" BU_SG_REL_ CIOM SG_ 2495638185 ExtraBBSlidable5thWheelStatus 450;
BA_REL_ "GenSigFirstTimeoutTime" BU_SG_REL_ HMIIOM SG_ 2495638185 ParkBrakeReleasePossible_stat 3000;
BA_REL_ "GenSigTimeoutTime" BU_SG_REL_ HMIIOM SG_ 2495638185 ParkBrakeReleasePossible_stat 450;
BA_REL_ "GenSigFirstTimeoutTime" BU_SG_REL_ VGGSECUSystem SG_ 2495638185 ParkBrakeReleasePossible_stat 3000;
BA_REL_ "GenSigTimeoutTime" BU_SG_REL_ VGGSECUSystem SG_ 2495638185 ParkBrakeReleasePossible_stat 450;
BA_REL_ "GenSigFirstTimeoutTime" BU_SG_REL_ TECU SG_ 2495638185 ParkBrakeReleasePossible_stat 3000;
BA_REL_ "GenSigTimeoutTime" BU_SG_REL_ TECU SG_ 2495638185 ParkBrakeReleasePossible_stat 450;
BA_REL_ "GenSigFirstTimeoutTime" BU_SG_REL_ CIOM SG_ 2495638185 LoadDistributionALDChangeACK_ISi 3000;
BA_REL_ "GenSigTimeoutTime" BU_SG_REL_ CIOM SG_ 2495638185 LoadDistributionALDChangeACK_ISi 450;
BA_REL_ "GenSigFirstTimeoutTime" BU_SG_REL_ HMIIOM SG_ 2495638185 LoadDistributionALDChangeACK_ISi 3000;
BA_REL_ "GenSigTimeoutTime" BU_SG_REL_ HMIIOM SG_ 2495638185 LoadDistributionALDChangeACK_ISi 450;
BA_REL_ "GenSigFirstTimeoutTime" BU_SG_REL_ HMIIOM SG_ 2495638185 ParkBrakeReleaseMode_ISig_4 3000;
BA_REL_ "GenSigTimeoutTime" BU_SG_REL_ HMIIOM SG_ 2495638185 ParkBrakeReleaseMode_ISig_4 450;
BA_REL_ "GenSigFirstTimeoutTime" BU_SG_REL_ HMIIOM SG_ 2495638185 ParkBrakeWorkshopMode_ISig_4 3000;
BA_REL_ "GenSigTimeoutTime" BU_SG_REL_ HMIIOM SG_ 2495638185 ParkBrakeWorkshopMode_ISig_4 450;
BA_REL_ "GenSigFirstTimeoutTime" BU_SG_REL_ CIOM SG_ 2495638185 ExtraBBContainerUnlockStatus 3000;
BA_REL_ "GenSigTimeoutTime" BU_SG_REL_ CIOM SG_ 2495638185 ExtraBBContainerUnlockStatus 450;
BA_REL_ "GenSigFirstTimeoutTime" BU_SG_REL_ BBM SG_ 2495638185 MainBeamRequest_status_ISig_4 3000;
BA_REL_ "GenSigTimeoutTime" BU_SG_REL_ BBM SG_ 2495638185 MainBeamRequest_status_ISig_4 450;
BA_REL_ "GenSigFirstTimeoutTime" BU_SG_REL_ DACU SG_ 2495638185 MainBeamRequest_status_ISig_4 3000;
BA_REL_ "GenSigTimeoutTime" BU_SG_REL_ DACU SG_ 2495638185 MainBeamRequest_status_ISig_4 600;
BA_REL_ "GenSigFirstTimeoutTime" BU_SG_REL_ CIOM SG_ 2495638185 ExtraBBCraneStatus_ISig_4 3000;
BA_REL_ "GenSigTimeoutTime" BU_SG_REL_ CIOM SG_ 2495638185 ExtraBBCraneStatus_ISig_4 450;
BA_REL_ "GenSigFirstTimeoutTime" BU_SG_REL_ BBM SG_ 2495638185 ExtraBBCraneStatus_ISig_4 3000;
BA_REL_ "GenSigTimeoutTime" BU_SG_REL_ BBM SG_ 2495638185 ExtraBBCraneStatus_ISig_4 450;
BA_REL_ "GenSigFirstTimeoutTime" BU_SG_REL_ EMS SG_ 2495638185 AirCompressorStatus 3000;
BA_REL_ "GenSigTimeoutTime" BU_SG_REL_ EMS SG_ 2495638185 AirCompressorStatus 450;
BA_REL_ "GenSigFirstTimeoutTime" BU_SG_REL_ TECU SG_ 2495638185 TrailerABSStatus_ISig_4 3000;
BA_REL_ "GenSigTimeoutTime" BU_SG_REL_ TECU SG_ 2495638185 TrailerABSStatus_ISig_4 450;
BA_REL_ "GenSigFirstTimeoutTime" BU_SG_REL_ HMIIOM SG_ 2495638185 TrailerABSStatus_ISig_4 3000;
BA_REL_ "GenSigTimeoutTime" BU_SG_REL_ HMIIOM SG_ 2495638185 TrailerABSStatus_ISig_4 450;
BA_REL_ "GenSigFirstTimeoutTime" BU_SG_REL_ EMS SG_ 2495638185 TrailerABSStatus_ISig_4 3000;
BA_REL_ "GenSigTimeoutTime" BU_SG_REL_ EMS SG_ 2495638185 TrailerABSStatus_ISig_4 450;
BA_REL_ "GenSigFirstTimeoutTime" BU_SG_REL_ DACU SG_ 2495638185 TrailerABSStatus_ISig_4 3000;
BA_REL_ "GenSigTimeoutTime" BU_SG_REL_ DACU SG_ 2495638185 TrailerABSStatus_ISig_4 500;
BA_REL_ "GenSigFirstTimeoutTime" BU_SG_REL_ EMS SG_ 2495638185 RegenInhibitVehicleHeight_ISig_4 3000;
BA_REL_ "GenSigTimeoutTime" BU_SG_REL_ EMS SG_ 2495638185 RegenInhibitVehicleHeight_ISig_4 450;
BA_REL_ "GenSigFirstTimeoutTime" BU_SG_REL_ BBM SG_ 2495638185 PoorAirPressureInfo_ISig_4 3000;
BA_REL_ "GenSigTimeoutTime" BU_SG_REL_ BBM SG_ 2495638185 PoorAirPressureInfo_ISig_4 450;
BA_REL_ "GenSigFirstTimeoutTime" BU_SG_REL_ HMIIOM SG_ 2495638185 PoorAirPressureInfo_ISig_4 3000;
BA_REL_ "GenSigTimeoutTime" BU_SG_REL_ HMIIOM SG_ 2495638185 PoorAirPressureInfo_ISig_4 500;
BA_REL_ "GenSigFirstTimeoutTime" BU_SG_REL_ VGGSECUSystem SG_ 2495638185 PoorAirPressureInfo_ISig_4 3000;
BA_REL_ "GenSigTimeoutTime" BU_SG_REL_ VGGSECUSystem SG_ 2495638185 PoorAirPressureInfo_ISig_4 450;
BA_REL_ "GenSigFirstTimeoutTime" BU_SG_REL_ BBM SG_ 2495638185 FogLightRearRequest_stat 3000;
BA_REL_ "GenSigTimeoutTime" BU_SG_REL_ BBM SG_ 2495638185 FogLightRearRequest_stat 450;
BA_REL_ "GenSigFirstTimeoutTime" BU_SG_REL_ BBM SG_ 2495638185 MainBeam_cmd_ISig_4 3000;
BA_REL_ "GenSigTimeoutTime" BU_SG_REL_ BBM SG_ 2495638185 MainBeam_cmd_ISig_4 600;
BA_REL_ "GenSigFirstTimeoutTime" BU_SG_REL_ HMIIOM SG_ 2495638185 FirstAxleLowerPrioSelected_ISig_ 3000;
BA_REL_ "GenSigTimeoutTime" BU_SG_REL_ HMIIOM SG_ 2495638185 FirstAxleLowerPrioSelected_ISig_ 450;
BA_REL_ "GenSigFirstTimeoutTime" BU_SG_REL_ BBM SG_ 2482995069 AuxSwitchBbLoad4_cmd 3000;
BA_REL_ "GenSigTimeoutTime" BU_SG_REL_ BBM SG_ 2482995069 AuxSwitchBbLoad4_cmd 300;
BA_REL_ "GenSigFirstTimeoutTime" BU_SG_REL_ CIOM SG_ 2482995069 AuxSwitchBbLoad1_Status_ISig_4 3000;
BA_REL_ "GenSigTimeoutTime" BU_SG_REL_ CIOM SG_ 2482995069 AuxSwitchBbLoad1_Status_ISig_4 300;
BA_REL_ "GenSigFirstTimeoutTime" BU_SG_REL_ BBM SG_ 2482995069 AuxSwitchBbLoad1_Status_ISig_4 3000;
BA_REL_ "GenSigTimeoutTime" BU_SG_REL_ BBM SG_ 2482995069 AuxSwitchBbLoad1_Status_ISig_4 300;
BA_REL_ "GenSigFirstTimeoutTime" BU_SG_REL_ HMIIOM SG_ 2482995069 AccPedalTestPresentationStatus 3000;
BA_REL_ "GenSigTimeoutTime" BU_SG_REL_ HMIIOM SG_ 2482995069 AccPedalTestPresentationStatus 300;
BA_REL_ "GenSigFirstTimeoutTime" BU_SG_REL_ VGGSECUSystem SG_ 2482995069 AccPedalTestPresentationStatus 3000;
BA_REL_ "GenSigTimeoutTime" BU_SG_REL_ VGGSECUSystem SG_ 2482995069 AccPedalTestPresentationStatus 300;
BA_REL_ "GenSigFirstTimeoutTime" BU_SG_REL_ BBM SG_ 2482995069 AuxSwitchBbLoad3_cmd 3000;
BA_REL_ "GenSigTimeoutTime" BU_SG_REL_ BBM SG_ 2482995069 AuxSwitchBbLoad3_cmd 300;
BA_REL_ "GenSigFirstTimeoutTime" BU_SG_REL_ HMIIOM SG_ 2482995069 BatterySOCTrustLevel_ISig_4 3000;
BA_REL_ "GenSigTimeoutTime" BU_SG_REL_ HMIIOM SG_ 2482995069 BatterySOCTrustLevel_ISig_4 300;
BA_REL_ "GenSigFirstTimeoutTime" BU_SG_REL_ CIOM SG_ 2482995069 AuxSwitchBbLoad4_Status_ISig_4 3000;
BA_REL_ "GenSigTimeoutTime" BU_SG_REL_ CIOM SG_ 2482995069 AuxSwitchBbLoad4_Status_ISig_4 300;
BA_REL_ "GenSigFirstTimeoutTime" BU_SG_REL_ BBM SG_ 2482995069 AuxSwitchBbLoad4_Status_ISig_4 3000;
BA_REL_ "GenSigTimeoutTime" BU_SG_REL_ BBM SG_ 2482995069 AuxSwitchBbLoad4_Status_ISig_4 300;
BA_REL_ "GenSigFirstTimeoutTime" BU_SG_REL_ BBM SG_ 2482995069 BrakeLightConvoy_rqst_ISig_4 3000;
BA_REL_ "GenSigTimeoutTime" BU_SG_REL_ BBM SG_ 2482995069 BrakeLightConvoy_rqst_ISig_4 500;
BA_REL_ "GenSigFirstTimeoutTime" BU_SG_REL_ CIOM SG_ 2482995069 DoorWarningLight_cmd_ISig_4 3000;
BA_REL_ "GenSigTimeoutTime" BU_SG_REL_ CIOM SG_ 2482995069 DoorWarningLight_cmd_ISig_4 300;
BA_REL_ "GenSigFirstTimeoutTime" BU_SG_REL_ HMIIOM SG_ 2482995069 BlackOutandConvoyMode_rqst_ISig_ 3000;
BA_REL_ "GenSigTimeoutTime" BU_SG_REL_ HMIIOM SG_ 2482995069 BlackOutandConvoyMode_rqst_ISig_ 300;
BA_REL_ "GenSigFirstTimeoutTime" BU_SG_REL_ DACU SG_ 2482995069 BlackOutandConvoyMode_rqst_ISig_ 3000;
BA_REL_ "GenSigTimeoutTime" BU_SG_REL_ DACU SG_ 2482995069 BlackOutandConvoyMode_rqst_ISig_ 300;
BA_REL_ "GenSigFirstTimeoutTime" BU_SG_REL_ BBM SG_ 2482995069 BlackOutandConvoyMode_rqst_ISig_ 3000;
BA_REL_ "GenSigTimeoutTime" BU_SG_REL_ BBM SG_ 2482995069 BlackOutandConvoyMode_rqst_ISig_ 300;
BA_REL_ "GenSigFirstTimeoutTime" BU_SG_REL_ DACU SG_ 2482995069 DirIndicatorRqstLights_stat 3000;
BA_REL_ "GenSigTimeoutTime" BU_SG_REL_ DACU SG_ 2482995069 DirIndicatorRqstLights_stat 300;
BA_REL_ "GenSigFirstTimeoutTime" BU_SG_REL_ BBM SG_ 2482995069 DirIndicatorRqstLights_stat 3000;
BA_REL_ "GenSigTimeoutTime" BU_SG_REL_ BBM SG_ 2482995069 DirIndicatorRqstLights_stat 300;
BA_REL_ "GenSigFirstTimeoutTime" BU_SG_REL_ HMIIOM SG_ 2482995069 DoubleFrontAxleSteeringWarning_I 3000;
BA_REL_ "GenSigTimeoutTime" BU_SG_REL_ HMIIOM SG_ 2482995069 DoubleFrontAxleSteeringWarning_I 300;
BA_REL_ "GenSigFirstTimeoutTime" BU_SG_REL_ HMIIOM SG_ 2482995069 ASLActive 3000;
BA_REL_ "GenSigTimeoutTime" BU_SG_REL_ HMIIOM SG_ 2482995069 ASLActive 300;
BA_REL_ "GenSigFirstTimeoutTime" BU_SG_REL_ BBM SG_ 2482995069 DippedBeamRequest_status 3000;
BA_REL_ "GenSigTimeoutTime" BU_SG_REL_ BBM SG_ 2482995069 DippedBeamRequest_status 300;
BA_REL_ "GenSigFirstTimeoutTime" BU_SG_REL_ CIOM SG_ 2482995069 AuxSwitchBbLoad3_Status_ISig_4 3000;
BA_REL_ "GenSigTimeoutTime" BU_SG_REL_ CIOM SG_ 2482995069 AuxSwitchBbLoad3_Status_ISig_4 300;
BA_REL_ "GenSigFirstTimeoutTime" BU_SG_REL_ BBM SG_ 2482995069 AuxSwitchBbLoad3_Status_ISig_4 3000;
BA_REL_ "GenSigTimeoutTime" BU_SG_REL_ BBM SG_ 2482995069 AuxSwitchBbLoad3_Status_ISig_4 300;
BA_REL_ "GenSigFirstTimeoutTime" BU_SG_REL_ CIOM SG_ 2482995069 DoorInstepLight_cmd_ISig_4 3000;
BA_REL_ "GenSigTimeoutTime" BU_SG_REL_ CIOM SG_ 2482995069 DoorInstepLight_cmd_ISig_4 300;
BA_REL_ "GenSigFirstTimeoutTime" BU_SG_REL_ BBM SG_ 2482995069 DRLRequest_status 3000;
BA_REL_ "GenSigTimeoutTime" BU_SG_REL_ BBM SG_ 2482995069 DRLRequest_status 300;
BA_REL_ "GenSigFirstTimeoutTime" BU_SG_REL_ BBM SG_ 2482995069 AuxSwitchBbLoad6_Status_ISig_4 3000;
BA_REL_ "GenSigTimeoutTime" BU_SG_REL_ BBM SG_ 2482995069 AuxSwitchBbLoad6_Status_ISig_4 300;
BA_REL_ "GenSigFirstTimeoutTime" BU_SG_REL_ CIOM SG_ 2482995069 AuxSwitchBbLoad6_Status_ISig_4 3000;
BA_REL_ "GenSigTimeoutTime" BU_SG_REL_ CIOM SG_ 2482995069 AuxSwitchBbLoad6_Status_ISig_4 300;
BA_REL_ "GenSigFirstTimeoutTime" BU_SG_REL_ CIOM SG_ 2482995069 AuxSwitchBbLoad2_Status_ISig_4 3000;
BA_REL_ "GenSigTimeoutTime" BU_SG_REL_ CIOM SG_ 2482995069 AuxSwitchBbLoad2_Status_ISig_4 300;
BA_REL_ "GenSigFirstTimeoutTime" BU_SG_REL_ BBM SG_ 2482995069 AuxSwitchBbLoad2_Status_ISig_4 3000;
BA_REL_ "GenSigTimeoutTime" BU_SG_REL_ BBM SG_ 2482995069 AuxSwitchBbLoad2_Status_ISig_4 300;
BA_REL_ "GenSigFirstTimeoutTime" BU_SG_REL_ BBM SG_ 2482995069 AuxSwitchBbLoad5_cmd 3000;
BA_REL_ "GenSigTimeoutTime" BU_SG_REL_ BBM SG_ 2482995069 AuxSwitchBbLoad5_cmd 300;
BA_REL_ "GenSigFirstTimeoutTime" BU_SG_REL_ BBM SG_ 2482995069 PBReleaseInhibit_EPBState_ISig_4 3000;
BA_REL_ "GenSigTimeoutTime" BU_SG_REL_ BBM SG_ 2482995069 PBReleaseInhibit_EPBState_ISig_4 300;
BA_REL_ "GenSigFirstTimeoutTime" BU_SG_REL_ HMIIOM SG_ 2482995069 ExtStaticTrailerBrake_Stat_ISig_ 3000;
BA_REL_ "GenSigTimeoutTime" BU_SG_REL_ HMIIOM SG_ 2482995069 ExtStaticTrailerBrake_Stat_ISig_ 300;
BA_REL_ "GenSigFirstTimeoutTime" BU_SG_REL_ BBM SG_ 2482995069 ExtStaticTrailerBrake_Stat_ISig_ 3000;
BA_REL_ "GenSigTimeoutTime" BU_SG_REL_ BBM SG_ 2482995069 ExtStaticTrailerBrake_Stat_ISig_ 300;
BA_REL_ "GenSigFirstTimeoutTime" BU_SG_REL_ CIOM SG_ 2482995069 AuxSwitchBbLoad5_Status_ISig_4 3000;
BA_REL_ "GenSigTimeoutTime" BU_SG_REL_ CIOM SG_ 2482995069 AuxSwitchBbLoad5_Status_ISig_4 300;
BA_REL_ "GenSigFirstTimeoutTime" BU_SG_REL_ BBM SG_ 2482995069 AuxSwitchBbLoad5_Status_ISig_4 3000;
BA_REL_ "GenSigTimeoutTime" BU_SG_REL_ BBM SG_ 2482995069 AuxSwitchBbLoad5_Status_ISig_4 300;
BA_REL_ "GenSigFirstTimeoutTime" BU_SG_REL_ BBM SG_ 2482995069 AuxSwitchBbLoad6_cmd 3000;
BA_REL_ "GenSigTimeoutTime" BU_SG_REL_ BBM SG_ 2482995069 AuxSwitchBbLoad6_cmd 300;
BA_REL_ "GenSigFirstTimeoutTime" BU_SG_REL_ TECU SG_ 2466234175 CCSetSpeed_ISig_4 3000;
BA_REL_ "GenSigTimeoutTime" BU_SG_REL_ TECU SG_ 2466234175 CCSetSpeed_ISig_4 210;
BA_REL_ "GenSigFirstTimeoutTime" BU_SG_REL_ BBM SG_ 2466234175 CCSetSpeed_ISig_4 3000;
BA_REL_ "GenSigTimeoutTime" BU_SG_REL_ BBM SG_ 2466234175 CCSetSpeed_ISig_4 210;
BA_REL_ "GenSigFirstTimeoutTime" BU_SG_REL_ DACU SG_ 2466234175 CCSetSpeed_ISig_4 3000;
BA_REL_ "GenSigTimeoutTime" BU_SG_REL_ DACU SG_ 2466234175 CCSetSpeed_ISig_4 600;
BA_REL_ "GenSigFirstTimeoutTime" BU_SG_REL_ HMIIOM SG_ 2466234175 CCSetSpeed_ISig_4 3000;
BA_REL_ "GenSigTimeoutTime" BU_SG_REL_ HMIIOM SG_ 2466234175 CCSetSpeed_ISig_4 210;
BA_REL_ "GenSigFirstTimeoutTime" BU_SG_REL_ BBM SG_ 2466234175 AcceleratorPedalQuality_ISig_4 3000;
BA_REL_ "GenSigTimeoutTime" BU_SG_REL_ BBM SG_ 2466234175 AcceleratorPedalQuality_ISig_4 210;
BA_REL_ "GenSigFirstTimeoutTime" BU_SG_REL_ CIOM SG_ 2466234175 CCStates_ISig_4 3000;
BA_REL_ "GenSigTimeoutTime" BU_SG_REL_ CIOM SG_ 2466234175 CCStates_ISig_4 210;
BA_REL_ "GenSigFirstTimeoutTime" BU_SG_REL_ DACU SG_ 2466234175 CCStates_ISig_4 3000;
BA_REL_ "GenSigTimeoutTime" BU_SG_REL_ DACU SG_ 2466234175 CCStates_ISig_4 210;
BA_REL_ "GenSigFirstTimeoutTime" BU_SG_REL_ HMIIOM SG_ 2466234175 CCStates_ISig_4 3000;
BA_REL_ "GenSigTimeoutTime" BU_SG_REL_ HMIIOM SG_ 2466234175 CCStates_ISig_4 210;
BA_REL_ "GenSigFirstTimeoutTime" BU_SG_REL_ BBM SG_ 2466234175 CCStates_ISig_4 3000;
BA_REL_ "GenSigTimeoutTime" BU_SG_REL_ BBM SG_ 2466234175 CCStates_ISig_4 210;
BA_REL_ "GenSigFirstTimeoutTime" BU_SG_REL_ HMIIOM SG_ 2466234175 CCIOM_ParkBrakeAlert_ISig_4 3000;
BA_REL_ "GenSigTimeoutTime" BU_SG_REL_ HMIIOM SG_ 2466234175 CCIOM_ParkBrakeAlert_ISig_4 210;
BA_REL_ "GenSigFirstTimeoutTime" BU_SG_REL_ DACU SG_ 2466234175 CCDeactivationWarning 3000;
BA_REL_ "GenSigTimeoutTime" BU_SG_REL_ DACU SG_ 2466234175 CCDeactivationWarning 210;
BA_REL_ "GenSigFirstTimeoutTime" BU_SG_REL_ BBM SG_ 2466234175 PrimaryAcctrPedalPosition_ISig_4 3000;
BA_REL_ "GenSigTimeoutTime" BU_SG_REL_ BBM SG_ 2466234175 PrimaryAcctrPedalPosition_ISig_4 210;
BA_REL_ "GenSigFirstTimeoutTime" BU_SG_REL_ HMIIOM SG_ 2466234175 CCNotificationReq_ISig_4 3000;
BA_REL_ "GenSigTimeoutTime" BU_SG_REL_ HMIIOM SG_ 2466234175 CCNotificationReq_ISig_4 210;
BA_REL_ "GenSigFirstTimeoutTime" BU_SG_REL_ CIOM SG_ 2466234175 AcceleratorPedalStatus_ISig_4 3000;
BA_REL_ "GenSigTimeoutTime" BU_SG_REL_ CIOM SG_ 2466234175 AcceleratorPedalStatus_ISig_4 210;
BA_REL_ "GenSigFirstTimeoutTime" BU_SG_REL_ BBM SG_ 2466234175 AcceleratorPedalStatus_ISig_4 3000;
BA_REL_ "GenSigTimeoutTime" BU_SG_REL_ BBM SG_ 2466234175 AcceleratorPedalStatus_ISig_4 210;
BA_REL_ "GenSigFirstTimeoutTime" BU_SG_REL_ CIOM SG_ 2466234175 LoadDistributionRequestedACK_ISi 3000;
BA_REL_ "GenSigTimeoutTime" BU_SG_REL_ CIOM SG_ 2466234175 LoadDistributionRequestedACK_ISi 210;
BA_REL_ "GenSigFirstTimeoutTime" BU_SG_REL_ CIOM SG_ 2466234175 ElectricalLoadReduction_rqst_ISi 3000;
BA_REL_ "GenSigTimeoutTime" BU_SG_REL_ CIOM SG_ 2466234175 ElectricalLoadReduction_rqst_ISi 500;
BA_REL_ "GenSigFirstTimeoutTime" BU_SG_REL_ HMIIOM SG_ 2466234175 FifthWheelLockingInformation_ISi 3000;
BA_REL_ "GenSigTimeoutTime" BU_SG_REL_ HMIIOM SG_ 2466234175 FifthWheelLockingInformation_ISi 500;
BA_REL_ "GenSigFirstTimeoutTime" BU_SG_REL_ HMIIOM SG_ 2466223295 CCBActiveStatus 3000;
BA_REL_ "GenSigTimeoutTime" BU_SG_REL_ HMIIOM SG_ 2466223295 CCBActiveStatus 180;
BA_REL_ "GenSigFirstTimeoutTime" BU_SG_REL_ HMIIOM SG_ 2466223295 ExtLightFreewheel_Ind 3000;
BA_REL_ "GenSigTimeoutTime" BU_SG_REL_ HMIIOM SG_ 2466223295 ExtLightFreewheel_Ind 180;
BA_REL_ "GenSigFirstTimeoutTime" BU_SG_REL_ DACU SG_ 2466223295 CCBSetSpeed 3000;
BA_REL_ "GenSigTimeoutTime" BU_SG_REL_ DACU SG_ 2466223295 CCBSetSpeed 180;
BA_REL_ "GenSigFirstTimeoutTime" BU_SG_REL_ TECU SG_ 2466223295 CCBSetSpeed 3000;
BA_REL_ "GenSigTimeoutTime" BU_SG_REL_ TECU SG_ 2466223295 CCBSetSpeed 180;
BA_REL_ "GenSigFirstTimeoutTime" BU_SG_REL_ HMIIOM SG_ 2466223295 CCBSetSpeed 3000;
BA_REL_ "GenSigTimeoutTime" BU_SG_REL_ HMIIOM SG_ 2466223295 CCBSetSpeed 180;
BA_REL_ "GenSigFirstTimeoutTime" BU_SG_REL_ HMIIOM SG_ 2466223295 ASLNotificationReq 3000;
BA_REL_ "GenSigTimeoutTime" BU_SG_REL_ HMIIOM SG_ 2466223295 ASLNotificationReq 180;
BA_REL_ "GenSigFirstTimeoutTime" BU_SG_REL_ HMIIOM SG_ 2466223295 GearRangeUnengaged_ISig_4 3000;
BA_REL_ "GenSigTimeoutTime" BU_SG_REL_ HMIIOM SG_ 2466223295 GearRangeUnengaged_ISig_4 180;
BA_REL_ "GenSigFirstTimeoutTime" BU_SG_REL_ DACU SG_ 2466223295 LaneChangeStatus_ISig_4 3000;
BA_REL_ "GenSigTimeoutTime" BU_SG_REL_ DACU SG_ 2466223295 LaneChangeStatus_ISig_4 180;
BA_REL_ "GenSigFirstTimeoutTime" BU_SG_REL_ CIOM SG_ 2466223295 ASLStates 3000;
BA_REL_ "GenSigTimeoutTime" BU_SG_REL_ CIOM SG_ 2466223295 ASLStates 180;
BA_REL_ "GenSigFirstTimeoutTime" BU_SG_REL_ HMIIOM SG_ 2466223295 ASLStates 3000;
BA_REL_ "GenSigTimeoutTime" BU_SG_REL_ HMIIOM SG_ 2466223295 ASLStates 180;
BA_REL_ "GenSigFirstTimeoutTime" BU_SG_REL_ HMIIOM SG_ 2466223295 ASLSetSpeed 3000;
BA_REL_ "GenSigTimeoutTime" BU_SG_REL_ HMIIOM SG_ 2466223295 ASLSetSpeed 180;
BA_REL_ "GenSigFirstTimeoutTime" BU_SG_REL_ BBM SG_ 2466223295 LongMotionDirection_ISig_4 3000;
BA_REL_ "GenSigTimeoutTime" BU_SG_REL_ BBM SG_ 2466223295 LongMotionDirection_ISig_4 180;
BA_REL_ "GenSigFirstTimeoutTime" BU_SG_REL_ CIOM SG_ 2466223295 LongMotionDirection_ISig_4 3000;
BA_REL_ "GenSigTimeoutTime" BU_SG_REL_ CIOM SG_ 2466223295 LongMotionDirection_ISig_4 120;
BA_REL_ "GenSigFirstTimeoutTime" BU_SG_REL_ CIOM SG_ 2466223295 LongMotionDirectionQual_ISig_4 3000;
BA_REL_ "GenSigTimeoutTime" BU_SG_REL_ CIOM SG_ 2466223295 LongMotionDirectionQual_ISig_4 120;
VAL_ 2495638185 MaintOilQuality 7 "OilQuality_NotAvailable" 6 "OilQuality_Error" 5 "OilQuality_NoSelectionMade" 4 "OilQuality_VDS4" 3 "OilQuality_VDS3" 2 "OilQuality_VDS2" 1 "OilQuality_VDSVDS3WithFixedInterval" 0 "OilQuality_NonVDS_VDS4WithFixedInterval" ;
VAL_ 2495638185 FrontParkBrakeOverrideInd_ISig_4 3 "FrontParkBrakeOverrideInd_NotAvailable" 2 "FrontParkBrakeOverrideInd_Error" 1 "FrontParkBrakeOverrideInd_FailedToOverride" 0 "FrontParkBrakeOverrideInd_OK" ;
VAL_ 2495638185 ECSLimpHomeNotification_ISig_4 7 "ECSLimpHomeNotification_NotAvailable" 6 "ECSLimpHomeNotification_Error" 5 "ECSLimpHomeNotification_LimpHomeMode5" 4 "ECSLimpHomeNotification_LimpHomeMode4" 3 "ECSLimpHomeNotification_LimpHomeMode3" 2 "ECSLimpHomeNotification_LimpHomeMode2" 1 "ECSLimpHomeNotification_LimpHomeMode1" 0 "ECSLimpHomeNotification_NoLimpHomeMode" ;
VAL_ 2495638185 MirrorHeatUnavailable_Ind 3 "InactiveActive_NotAvailable" 2 "InactiveActive_Error" 1 "InactiveActive_Active" 0 "InactiveActive_Inactive" ;
VAL_ 2495638185 MaintenanceResetStatus 7 "MaintenanceResetStatus_NotAvailable" 6 "MaintenanceResetStatus_Error" 5 "MaintenanceResetStatus_ResetFailed" 4 "MaintenanceResetStatus_ResetSuccessful" 3 "MaintenanceResetStatus_ResetOngoing" 2 "MaintenanceResetStatus_Spare_02" 1 "MaintenanceResetStatus_Spare_01" 0 "MaintenanceResetStatus_NoResetRequested" ;
VAL_ 2495638185 ParkBrakeApplicationMode 7 "ParkBrakeApplicationMode_NotAvailable" 6 "ParkBrakeApplicationMode_Error" 5 "ParkBrakeApplicationMode_AutomaticInBackup" 4 "ParkBrakeApplicationMode_ExternalDemand" 3 "ParkBrakeApplicationMode_Automatically" 2 "ParkBrakeApplicationMode_ManuallyAtStandstill" 1 "ParkBrakeApplicationMode_ManuallyInDriving" 0 "ParkBrakeApplicationMode_Idle" ;
VAL_ 2495638185 MaintOilReset 3 "Request_NotAvailable" 2 "Request_Error" 1 "Request_RequestActive" 0 "Request_NotRequested" ;
VAL_ 2495638185 RssInhibStartEngine_rqst_ISig_4 3 "OffOn_NotAvailable" 2 "OffOn_Error" 1 "OffOn_On" 0 "OffOn_Off" ;
VAL_ 2495638185 PositionLightRequest_status 3 "OffOn_NotAvailable" 2 "OffOn_Error" 1 "OffOn_On" 0 "OffOn_Off" ;
VAL_ 2495638185 ExtraBBTailLiftStatus_ISig_4 3 "InactiveActive_NotAvailable" 2 "InactiveActive_Error" 1 "InactiveActive_Active" 0 "InactiveActive_Inactive" ;
VAL_ 2495638185 MaintenanceNotification_ISig_4 7 "MaintenanceNotification_NotAvailable" 6 "MaintenanceNotification_Error" 5 "MaintenanceNotification_Spare_02" 4 "MaintenanceNotification_Spare_01" 3 "MaintenanceNotification_Spare" 2 "MaintenanceNotification_WarningNotification" 1 "MaintenanceNotification_PreWarningNotification" 0 "MaintenanceNotification_NoNotification" ;
VAL_ 2495638185 ExtraBBSlidable5thWheelStatus 3 "InactiveActive_NotAvailable" 2 "InactiveActive_Error" 1 "InactiveActive_Active" 0 "InactiveActive_Inactive" ;
VAL_ 2495638185 ParkBrakeReleasePossible_stat 3 "ParkBrakeReleasePossible_stat_NotAvailable" 2 "ParkBrakeReleasePossible_stat_Error" 1 "ParkBrakeReleasePossible_stat_Possible_PressureOK" 0 "ParkBrakeReleasePossible_stat_NotPossible_LowerPressure" ;
VAL_ 2495638185 LoadDistributionALDChangeACK_ISi 7 "LoadDistributionALDChangeACK_NotAvailable" 6 "LoadDistributionALDChangeACK_Error" 5 "LoadDistributionALDChangeACK_SystemDeniedVersatile" 4 "LoadDistributionALDChangeACK_Spare_01" 3 "LoadDistributionALDChangeACK_Spare" 2 "LoadDistributionALDChangeACK_LoadShiftDeniedOverspeed" 1 "LoadDistributionALDChangeACK_ChangeAcknowledged" 0 "LoadDistributionALDChangeACK_NoAction" ;
VAL_ 2495638185 ParkBrakeReleaseMode_ISig_4 7 "ParkBrakeReleaseMode_NotAvailable" 6 "ParkBrakeReleaseMode_Error" 5 "ParkBrakeReleaseMode_AutomaticBackup" 4 "ParkBrakeReleaseMode_ExternalDemand" 3 "ParkBrakeReleaseMode_Automatically" 2 "ParkBrakeReleaseMode_ManuallyAtStandstill" 1 "ParkBrakeReleaseMode_ManuallyInDrivingOrNotUsed" 0 "ParkBrakeReleaseMode_Idle" ;
VAL_ 2495638185 ParkBrakeWorkshopMode_ISig_4 3 "ParkBrakeWorkshopMode_NotAvailable" 2 "ParkBrakeWorkshopMode_Error" 1 "ParkBrakeWorkshopMode_WorkshopMode" 0 "ParkBrakeWorkshopMode_NormalMode" ;
VAL_ 2495638185 ExtraBBContainerUnlockStatus 3 "InactiveActive_NotAvailable" 2 "InactiveActive_Error" 1 "InactiveActive_Active" 0 "InactiveActive_Inactive" ;
VAL_ 2495638185 MainBeamRequest_status_ISig_4 3 "OffOn_NotAvailable" 2 "OffOn_Error" 1 "OffOn_On" 0 "OffOn_Off" ;
VAL_ 2495638185 ExtraBBCraneStatus_ISig_4 7 "ExtraBBCraneStatus_NotAvailable" 6 "ExtraBBCraneStatus_Error" 5 "ExtraBBCraneStatus_Spare_02" 4 "ExtraBBCraneStatus_Spare_01" 3 "ExtraBBCraneStatus_Spare" 2 "ExtraBBCraneStatus_Active" 1 "ExtraBBCraneStatus_Enable" 0 "ExtraBBCraneStatus_Disable" ;
VAL_ 2495638185 AirCompressorStatus 3 "InactiveActive_NotAvailable" 2 "InactiveActive_Error" 1 "InactiveActive_Active" 0 "InactiveActive_Inactive" ;
VAL_ 2495638185 TrailerABSStatus_ISig_4 3 "TrailerABSStatus_NotAvailable" 2 "TrailerABSStatus_ErrorIndicator" 1 "TrailerABSStatus_OK" 0 "TrailerABSStatus_Error" ;
VAL_ 2495638185 RegenInhibitVehicleHeight_ISig_4 3 "ActiveStatus_NotAvailable" 2 "ActiveStatus_Error" 1 "ActiveStatus_Active" 0 "ActiveStatus_NotActive" ;
VAL_ 2495638185 PoorAirPressureInfo_ISig_4 3 "PoorAirPressureInfo_NotAvailable" 2 "PoorAirPressureInfo_Error" 1 "PoorAirPressureInfo_PoorAirPressure" 0 "PoorAirPressureInfo_NormalPressure" ;
VAL_ 2495638185 FogLightRearRequest_stat 3 "InactiveActive_NotAvailable" 2 "InactiveActive_Error" 1 "InactiveActive_Active" 0 "InactiveActive_Inactive" ;
VAL_ 2495638185 MainBeam_cmd_ISig_4 7 "MainBeam_cmd_NotAvailable" 6 "MainBeam_cmd_SpareValue_03" 5 "MainBeam_cmd_SpareValue_02" 4 "MainBeam_cmd_SpareValue_01" 3 "MainBeam_cmd_SpareValue" 2 "MainBeam_cmd_MainBeamFlashOn" 1 "MainBeam_cmd_MainBeamOn" 0 "MainBeam_cmd_MainBeamOff" ;
VAL_ 2495638185 FirstAxleLowerPrioSelected_ISig_ 7 "FirstAxleLowerPrio_NotAvailable" 6 "FirstAxleLowerPrio_Error" 5 "FirstAxleLowerPrio_Reserved_03" 4 "FirstAxleLowerPrio_Reserved_02" 3 "FirstAxleLowerPrio_Reserved_01" 2 "FirstAxleLowerPrio_Reserved" 1 "FirstAxleLowerPrio_LowerPusher" 0 "FirstAxleLowerPrio_LowerTag" ;
VAL_ 2482995069 AuxSwitchBbLoad4_cmd 3 "NotDriven_Driven_NotAvailable" 2 "NotDriven_Driven_Error" 1 "NotDriven_Driven_Driven" 0 "NotDriven_Driven_NotDriven" ;
VAL_ 2482995069 AuxSwitchBbLoad1_Status_ISig_4 3 "InactiveActive_NotAvailable" 2 "InactiveActive_Error" 1 "InactiveActive_Active" 0 "InactiveActive_Inactive" ;
VAL_ 2482995069 AccPedalTestPresentationStatus 7 "PedalTestValidationStatus_NotAvailable" 6 "PedalTestValidationStatus_Error" 5 "PedalTestValidationStatus_TestFailed" 4 "PedalTestValidationStatus_BothSensorsFaulty" 3 "PedalTestValidationStatus_Step3" 2 "PedalTestValidationStatus_Step2" 1 "PedalTestValidationStatus_Step1" 0 "PedalTestValidationStatus_Inactive" ;
VAL_ 2482995069 AuxSwitchBbLoad3_cmd 3 "NotDriven_Driven_NotAvailable" 2 "NotDriven_Driven_Error" 1 "NotDriven_Driven_Driven" 0 "NotDriven_Driven_NotDriven" ;
VAL_ 2482995069 AuxSwitchBbLoad4_Status_ISig_4 3 "InactiveActive_NotAvailable" 2 "InactiveActive_Error" 1 "InactiveActive_Active" 0 "InactiveActive_Inactive" ;
VAL_ 2482995069 BrakeLightConvoy_rqst_ISig_4 3 "OffOn_NotAvailable" 2 "OffOn_Error" 1 "OffOn_On" 0 "OffOn_Off" ;
VAL_ 2482995069 DoorWarningLight_cmd_ISig_4 3 "OffOn_NotAvailable" 2 "OffOn_Error" 1 "OffOn_On" 0 "OffOn_Off" ;
VAL_ 2482995069 BlackOutandConvoyMode_rqst_ISig_ 7 "BlackOutandConvoyMode_rqst_NotAvailable" 6 "BlackOutandConvoyMode_rqst_Error" 5 "BlackOutandConvoyMode_rqst_SpareValue_02" 4 "BlackOutandConvoyMode_rqst_SpareValue_01" 3 "BlackOutandConvoyMode_rqst_SpareValue" 2 "BlackOutandConvoyMode_rqst_ConvoyMode" 1 "BlackOutandConvoyMode_rqst_BlackOutMode" 0 "BlackOutandConvoyMode_rqst_NormalMode" ;
VAL_ 2482995069 DirIndicatorRqstLights_stat 7 "DirIndicatorRqstLights_stat_NotAvailable" 6 "DirIndicatorRqstLights_stat_Error" 5 "DirIndicatorRqstLights_stat_SpareValue_01" 4 "DirIndicatorRqstLights_stat_SpareValue" 3 "DirIndicatorRqstLights_stat_RightAndLeftON_Hazard" 2 "DirIndicatorRqstLights_stat_RightDirectionIndicatorON" 1 "DirIndicatorRqstLights_stat_LeftDirectionIndicatorON" 0 "DirIndicatorRqstLights_stat_DirectionIndicatorsOFF" ;
VAL_ 2482995069 DoubleFrontAxleSteeringWarning_I 3 "DoubleFrontAxleSteeringWarning_NotAvailiable" 2 "DoubleFrontAxleSteeringWarning_Error" 1 "DoubleFrontAxleSteeringWarning_DoubleFrAxleSteeringBackupMode" 0 "DoubleFrontAxleSteeringWarning_NoRequest" ;
VAL_ 2482995069 ASLActive 3 "OffOn_NotAvailable" 2 "OffOn_Error" 1 "OffOn_On" 0 "OffOn_Off" ;
VAL_ 2482995069 DippedBeamRequest_status 3 "OffOn_NotAvailable" 2 "OffOn_Error" 1 "OffOn_On" 0 "OffOn_Off" ;
VAL_ 2482995069 AuxSwitchBbLoad3_Status_ISig_4 3 "InactiveActive_NotAvailable" 2 "InactiveActive_Error" 1 "InactiveActive_Active" 0 "InactiveActive_Inactive" ;
VAL_ 2482995069 DoorInstepLight_cmd_ISig_4 3 "OffOn_NotAvailable" 2 "OffOn_Error" 1 "OffOn_On" 0 "OffOn_Off" ;
VAL_ 2482995069 DRLRequest_status 3 "OffOn_NotAvailable" 2 "OffOn_Error" 1 "OffOn_On" 0 "OffOn_Off" ;
VAL_ 2482995069 AuxSwitchBbLoad6_Status_ISig_4 3 "InactiveActive_NotAvailable" 2 "InactiveActive_Error" 1 "InactiveActive_Active" 0 "InactiveActive_Inactive" ;
VAL_ 2482995069 AuxSwitchBbLoad2_Status_ISig_4 3 "InactiveActive_NotAvailable" 2 "InactiveActive_Error" 1 "InactiveActive_Active" 0 "InactiveActive_Inactive" ;
VAL_ 2482995069 AuxSwitchBbLoad5_cmd 3 "NotDriven_Driven_NotAvailable" 2 "NotDriven_Driven_Error" 1 "NotDriven_Driven_Driven" 0 "NotDriven_Driven_NotDriven" ;
VAL_ 2482995069 PBReleaseInhibit_EPBState_ISig_4 7 "PBReleaseInhibit_State_NotAvailable" 6 "PBReleaseInhibit_State_Error" 5 "PBReleaseInhibit_State_AutoReleaseCommandBeingInhibited" 4 "PBReleaseInhibit_State_XPRReleaseCommandBeingInhibited" 3 "PBReleaseInhibit_State_ManualReleaseCommandBeingInhibited" 2 "PBReleaseInhibit_State_Active" 1 "PBReleaseInhibit_State_FullyOperationalNotActive" 0 "PBReleaseInhibit_State_NotOperational" ;
VAL_ 2482995069 ExtStaticTrailerBrake_Stat_ISig_ 3 "InactiveActive_NotAvailable" 2 "InactiveActive_Error" 1 "InactiveActive_Active" 0 "InactiveActive_Inactive" ;
VAL_ 2482995069 AuxSwitchBbLoad5_Status_ISig_4 3 "InactiveActive_NotAvailable" 2 "InactiveActive_Error" 1 "InactiveActive_Active" 0 "InactiveActive_Inactive" ;
VAL_ 2482995069 AuxSwitchBbLoad6_cmd 3 "NotDriven_Driven_NotAvailable" 2 "NotDriven_Driven_Error" 1 "NotDriven_Driven_Driven" 0 "NotDriven_Driven_NotDriven" ;
VAL_ 2466234175 AcceleratorPedalQuality_ISig_4 3 "PrimaryAcceleratorPedalQuality_NotAvailable" 2 "PrimaryAcceleratorPedalQuality_ErrorMode" 1 "PrimaryAcceleratorPedalQuality_DowngradedMode" 0 "PrimaryAcceleratorPedalQuality_NormalMode" ;
VAL_ 2466234175 CCStates_ISig_4 15 "CCStates_NotAvailable" 14 "CCStates_Error" 13 "CCStates_Spare_7" 12 "CCStates_Spare_6" 11 "CCStates_Spare_5" 10 "CCStates_Spare_4" 9 "CCStates_Spare_3" 8 "CCStates_Spare_2" 7 "CCStates_Spare_1" 6 "CCStates_Driver_Override" 5 "CCStates_Set" 4 "CCStates_Resume" 3 "CCStates_Decelerate" 2 "CCStates_Accelerate" 1 "CCStates_Hold" 0 "CCStates_OffDisabled" ;
VAL_ 2466234175 CCIOM_ParkBrakeAlert_ISig_4 3 "Alert_NotAvailable" 2 "Alert_Error" 1 "Alert_Alert" 0 "Alert_NoAlert" ;
VAL_ 2466234175 CCDeactivationWarning 3 "OffOn_NotAvailable" 2 "OffOn_Error" 1 "OffOn_On" 0 "OffOn_Off" ;
VAL_ 2466234175 CCNotificationReq_ISig_4 15 "CCNotificationReq_NotAvailable" 14 "CCNotificationReq_Error" 13 "CCNotificationReq_Spare_6" 12 "CCNotificationReq_Spare_5" 11 "CCNotificationReq_Spare_4" 10 "CCNotificationReq_Spare_3" 9 "CCNotificationReq_Spare_2" 8 "CCNotificationReq_activation_failed_brake_pedal_check" 7 "CCNotificationReq_Deactivation_warning" 6 "CCNotificationReq_Activation_failed_error" 5 "CCNotificationReq_Activation_stop_braking" 4 "CCNotificationReq_Activation_failed_low_speed" 3 "CCNotificationReq_Overridden_manual_braking" 2 "CCNotificationReq_Overridden_manual_acceleration" 1 "CCNotificationReq_Overspeed_warning" 0 "CCNotificationReq_No_request" ;
VAL_ 2466234175 AcceleratorPedalStatus_ISig_4 7 "AcceleratorPedalStatus_NotAvailable" 6 "AcceleratorPedalStatus_Error" 5 "AcceleratorPedalStatus_Spare3" 4 "AcceleratorPedalStatus_Spare2" 3 "AcceleratorPedalStatus_Spare1" 2 "AcceleratorPedalStatus_PrimAndSecPedalInhibited" 1 "AcceleratorPedalStatus_SecPedActPrimPedNotAct" 0 "AcceleratorPedalStatus_SecPedNotActPrimPedAct" ;
VAL_ 2466234175 LoadDistributionRequestedACK_ISi 7 "LoadDistributionRequestedACK_NotAvailable" 6 "LoadDistributionRequestedACK_Error" 5 "LoadDistributionRequestedACK_SystemDeniedVersatile" 4 "LoadDistributionRequestedACK_Reserved2" 3 "LoadDistributionRequestedACK_Reserved1" 2 "LoadDistributionRequestedACK_LoadShiftDeniedFALIMOverload" 1 "LoadDistributionRequestedACK_ChangeAcknowledged" 0 "LoadDistributionRequestedACK_NoAction" ;
VAL_ 2466234175 ElectricalLoadReduction_rqst_ISi 7 "ElectricalLoadReduction_rqst_NotAvailable" 6 "ElectricalLoadReduction_rqst_Error" 5 "ElectricalLoadReduction_rqst_SpareValue_02" 4 "ElectricalLoadReduction_rqst_SpareValue_01" 3 "ElectricalLoadReduction_rqst_SpareValue" 2 "ElectricalLoadReduction_rqst_Level2Request" 1 "ElectricalLoadReduction_rqst_Level1Request" 0 "ElectricalLoadReduction_rqst_NoRequest" ;
VAL_ 2466234175 FifthWheelLockingInformation_ISi 15 "FifthWheelLockingInformation_NotAvailable" 14 "FifthWheelLockingInformation_Error" 13 "FifthWheelLockingInformation_Spare_07" 12 "FifthWheelLockingInformation_Spare_06" 11 "FifthWheelLockingInformation_Spare_05" 10 "FifthWheelLockingInformation_Spare_04" 9 "FifthWheelLockingInformation_Spare_03" 8 "FifthWheelLockingInformation_Spare_02" 7 "FifthWheelLockingInformation_Spare_01" 6 "FifthWheelLockingInformation_Spare" 5 "FifthWheelLockingInformation_5thWheelSystemError" 4 "FifthWheelLockingInformation_TrailerNotCorrectlyCoupled" 3 "FifthWheelLockingInformation_HandleLockedTrailerRightConnected" 2 "FifthWheelLockingInformation_KingPinEndPosTrailerPlateInContact" 1 "FifthWheelLockingInformation_TrailerPlateInContactW_semitrailer" 0 "FifthWheelLockingInformation_TractorAlone" ;
VAL_ 2466223295 CCBActiveStatus 3 "InactiveActive_NotAvailable" 2 "InactiveActive_Error" 1 "InactiveActive_Active" 0 "InactiveActive_Inactive" ;
VAL_ 2466223295 ExtLightFreewheel_Ind 7 "LightFreewheel_Ind_NotAvailable" 6 "LightFreewheel_Ind_Error" 5 "LightFreewheel_Ind_AHS_OFF" 4 "LightFreewheel_Ind_AHS_ON" 3 "LightFreewheel_Ind_Drive" 2 "LightFreewheel_Ind_Park" 1 "LightFreewheel_Ind_DRL_Auto" 0 "LightFreewheel_Ind_NoIndication" ;
VAL_ 2466223295 ASLNotificationReq 7 "ASLNotificationReq_NotAvailable" 6 "ASLNotificationReq_Error" 5 "ASLNotificationReq_Spare" 4 "ASLNotificationReq_DeactivationWarning" 3 "ASLNotificationReq_DeactivationFailedError" 2 "ASLNotificationReq_ActivationFailedLowSpeed" 1 "ASLNotificationReq_OverspeedWarning" 0 "ASLNotificationReq_NoRequest" ;
VAL_ 2466223295 GearRangeUnengaged_ISig_4 3 "GearInhibation_NotAvailable" 2 "GearInhibation_Error" 1 "GearInhibation_GearChangeInhibited" 0 "GearInhibation_NoInhibation" ;
VAL_ 2466223295 LaneChangeStatus_ISig_4 15 "LaneChangeStatus_NotAvailable" 14 "LaneChangeStatus_Error" 13 "LaneChangeStatus_Spare11" 12 "LaneChangeStatus_Spare10" 11 "LaneChangeStatus_Spare9" 10 "LaneChangeStatus_Spare8" 9 "LaneChangeStatus_Spare7" 8 "LaneChangeStatus_Spare6" 7 "LaneChangeStatus_Spare5" 6 "LaneChangeStatus_Spare4" 5 "LaneChangeStatus_Spare3" 4 "LaneChangeStatus_Spare2" 3 "LaneChangeStatus_Spare1" 2 "LaneChangeStatus_RightLaneChangeIntention" 1 "LaneChangeStatus_LeftLaneChangeIntention" 0 "LaneChangeStatus_NotActive" ;
VAL_ 2466223295 ASLStates 15 "ASLStates_NotAvailable" 14 "ASLStates_Error" 6 "ASLStates_Driver_override" 5 "ASLStates_Set" 4 "ASLStates_Resume" 3 "ASLStates_Decelerate" 2 "ASLStates_Accelerate" 1 "ASLStates_Hold" 0 "ASLStates_Off_disabled" ;
VAL_ 2466223295 LongMotionDirection_ISig_4 7 "LongMotionDirection_NotAvailable" 6 "LongMotionDirection_Error" 5 "LongMotionDirection_Spare3" 4 "LongMotionDirection_Spare2" 3 "LongMotionDirection_Undetermined" 2 "LongMotionDirection_Backward" 1 "LongMotionDirection_Forward" 0 "LongMotionDirection_Stationary" ;
VAL_ 2466223295 LongMotionDirectionQual_ISig_4 3 "LongMotionDirectionQual_NotAvailable" 2 "LongMotionDirectionQual_OEM_Reserved2" 1 "LongMotionDirectionQual_OEM_Reserved1" 0 "LongMotionDirectionQual_UsingGearbox" ;
